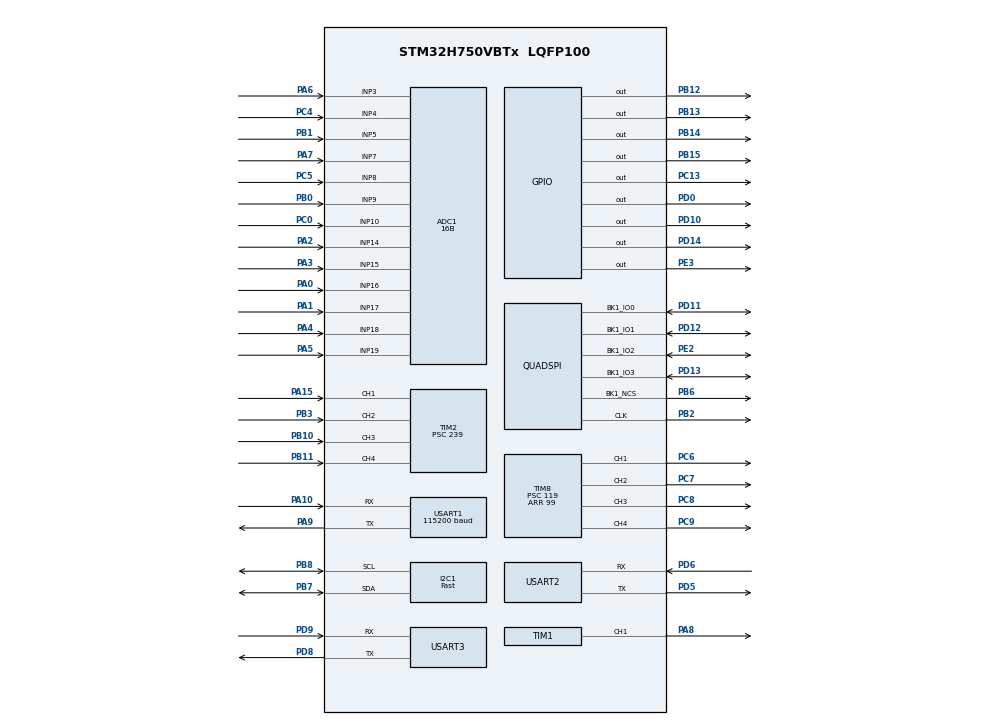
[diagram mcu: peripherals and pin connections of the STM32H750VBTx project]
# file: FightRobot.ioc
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ADC1.Channel-0\#ChannelRegularConversion=ADC_CHANNEL_3
ADC1.Channel-1\#ChannelRegularConversion=ADC_CHANNEL_4
ADC1.Channel-10\#ChannelRegularConversion=ADC_CHANNEL_17
ADC1.Channel-11\#ChannelRegularConversion=ADC_CHANNEL_18
ADC1.Channel-12\#ChannelRegularConversion=ADC_CHANNEL_19
ADC1.Channel-2\#ChannelRegularConversion=ADC_CHANNEL_5
ADC1.Channel-3\#ChannelRegularConversion=ADC_CHANNEL_7
ADC1.Channel-4\#ChannelRegularConversion=ADC_CHANNEL_8
ADC1.Channel-5\#ChannelRegularConversion=ADC_CHANNEL_9
ADC1.Channel-6\#ChannelRegularConversion=ADC_CHANNEL_10
ADC1.Channel-7\#ChannelRegularConversion=ADC_CHANNEL_14
ADC1.Channel-8\#ChannelRegularConversion=ADC_CHANNEL_15
ADC1.Channel-9\#ChannelRegularConversion=ADC_CHANNEL_16
ADC1.ClockPrescaler=ADC_CLOCK_ASYNC_DIV8
ADC1.ClockPrescalerADC3=ADC_CLOCK_ASYNC_DIV8
ADC1.ContinuousConvMode=ENABLE
ADC1.ConversionDataManagement=ADC_CONVERSIONDATA_DMA_CIRCULAR
ADC1.DiscontinuousConvMode=DISABLE
ADC1.EOCSelection=ADC_EOC_SEQ_CONV
ADC1.NbrOfConversion=13
ADC1.NbrOfConversionFlag=1
ADC1.OffsetNumber-0\#ChannelRegularConversion=ADC_OFFSET_NONE
ADC1.OffsetNumber-1\#ChannelRegularConversion=ADC_OFFSET_NONE
ADC1.OffsetNumber-10\#ChannelRegularConversion=ADC_OFFSET_NONE
ADC1.OffsetNumber-11\#ChannelRegularConversion=ADC_OFFSET_NONE
ADC1.OffsetNumber-12\#ChannelRegularConversion=ADC_OFFSET_NONE
ADC1.OffsetNumber-2\#ChannelRegularConversion=ADC_OFFSET_NONE
ADC1.OffsetNumber-3\#ChannelRegularConversion=ADC_OFFSET_NONE
ADC1.OffsetNumber-4\#ChannelRegularConversion=ADC_OFFSET_NONE
ADC1.OffsetNumber-5\#ChannelRegularConversion=ADC_OFFSET_NONE
ADC1.OffsetNumber-6\#ChannelRegularConversion=ADC_OFFSET_NONE
ADC1.OffsetNumber-7\#ChannelRegularConversion=ADC_OFFSET_NONE
ADC1.OffsetNumber-8\#ChannelRegularConversion=ADC_OFFSET_NONE
ADC1.OffsetNumber-9\#ChannelRegularConversion=ADC_OFFSET_NONE
ADC1.OffsetSignedSaturation-0\#ChannelRegularConversion=DISABLE
ADC1.OffsetSignedSaturation-1\#ChannelRegularConversion=DISABLE
ADC1.OffsetSignedSaturation-10\#ChannelRegularConversion=DISABLE
ADC1.OffsetSignedSaturation-11\#ChannelRegularConversion=DISABLE
ADC1.OffsetSignedSaturation-12\#ChannelRegularConversion=DISABLE
ADC1.OffsetSignedSaturation-2\#ChannelRegularConversion=DISABLE
ADC1.OffsetSignedSaturation-3\#ChannelRegularConversion=DISABLE
ADC1.OffsetSignedSaturation-4\#ChannelRegularConversion=DISABLE
ADC1.OffsetSignedSaturation-5\#ChannelRegularConversion=DISABLE
ADC1.OffsetSignedSaturation-6\#ChannelRegularConversion=DISABLE
ADC1.OffsetSignedSaturation-7\#ChannelRegularConversion=DISABLE
ADC1.OffsetSignedSaturation-8\#ChannelRegularConversion=DISABLE
ADC1.OffsetSignedSaturation-9\#ChannelRegularConversion=DISABLE
ADC1.Overrun=ADC_OVR_DATA_OVERWRITTEN
ADC1.OversamplingMode=ENABLE
ADC1.Rank-0\#ChannelRegularConversion=1
ADC1.Rank-1\#ChannelRegularConversion=2
ADC1.Rank-10\#ChannelRegularConversion=11
ADC1.Rank-11\#ChannelRegularConversion=12
ADC1.Rank-12\#ChannelRegularConversion=13
ADC1.Rank-2\#ChannelRegularConversion=3
ADC1.Rank-3\#ChannelRegularConversion=4
ADC1.Rank-4\#ChannelRegularConversion=5
ADC1.Rank-5\#ChannelRegularConversion=6
ADC1.Rank-6\#ChannelRegularConversion=7
ADC1.Rank-7\#ChannelRegularConversion=8
ADC1.Rank-8\#ChannelRegularConversion=9
ADC1.Rank-9\#ChannelRegularConversion=10
ADC1.Ratio=16
ADC1.Resolution=ADC_RESOLUTION_16B
ADC1.RightBitShift=ADC_RIGHTBITSHIFT_4
ADC1.SamplingTime-0\#ChannelRegularConversion=ADC_SAMPLETIME_64CYCLES_5
ADC1.SamplingTime-1\#ChannelRegularConversion=ADC_SAMPLETIME_64CYCLES_5
ADC1.SamplingTime-10\#ChannelRegularConversion=ADC_SAMPLETIME_64CYCLES_5
ADC1.SamplingTime-11\#ChannelRegularConversion=ADC_SAMPLETIME_64CYCLES_5
ADC1.SamplingTime-12\#ChannelRegularConversion=ADC_SAMPLETIME_64CYCLES_5
ADC1.SamplingTime-2\#ChannelRegularConversion=ADC_SAMPLETIME_64CYCLES_5
ADC1.SamplingTime-3\#ChannelRegularConversion=ADC_SAMPLETIME_64CYCLES_5
ADC1.SamplingTime-4\#ChannelRegularConversion=ADC_SAMPLETIME_64CYCLES_5
ADC1.SamplingTime-5\#ChannelRegularConversion=ADC_SAMPLETIME_64CYCLES_5
ADC1.SamplingTime-6\#ChannelRegularConversion=ADC_SAMPLETIME_64CYCLES_5
ADC1.SamplingTime-7\#ChannelRegularConversion=ADC_SAMPLETIME_64CYCLES_5
ADC1.SamplingTime-8\#ChannelRegularConversion=ADC_SAMPLETIME_64CYCLES_5
ADC1.SamplingTime-9\#ChannelRegularConversion=ADC_SAMPLETIME_64CYCLES_5
ADC1.master=1
CORTEX_M7.AccessPermission_Spec=MPU_REGION_FULL_ACCESS
CORTEX_M7.BaseAddress_Spec=0x24000000
CORTEX_M7.CPU_DCache=Enabled
CORTEX_M7.CPU_ICache=Enabled
CORTEX_M7.DisableExec_Spec=MPU_INSTRUCTION_ACCESS_ENABLE
CORTEX_M7.Enable-Cortex_Memory_Protection_Unit_Region15_Settings=__NULL
CORTEX_M7.Enable-Cortex_Memory_Protection_Unit_Region1_Settings=__NULL
CORTEX_M7.Enable-Cortex_Memory_Protection_Unit_Region2_Settings=__NULL
CORTEX_M7.IsShareable_Spec=MPU_ACCESS_NOT_SHAREABLE
CORTEX_M7.MPU_Control=MPU_HFNMI_PRIVDEF
CORTEX_M7.Size_Spec=MPU_REGION_SIZE_512KB
CORTEX_M7.SubRegionDisable_Spec=0x00
CORTEX_M7.TypeExtField_Spec=MPU_TEX_LEVEL1
CORTEX_M7.default_mode_Activation=1
Dma.ADC1.4.Direction=DMA_PERIPH_TO_MEMORY
Dma.ADC1.4.EventEnable=DISABLE
Dma.ADC1.4.FIFOMode=DMA_FIFOMODE_DISABLE
Dma.ADC1.4.Instance=DMA1_Stream0
Dma.ADC1.4.MemDataAlignment=DMA_MDATAALIGN_HALFWORD
Dma.ADC1.4.MemInc=DMA_MINC_ENABLE
Dma.ADC1.4.Mode=DMA_CIRCULAR
Dma.ADC1.4.PeriphDataAlignment=DMA_PDATAALIGN_HALFWORD
Dma.ADC1.4.PeriphInc=DMA_PINC_DISABLE
Dma.ADC1.4.Polarity=HAL_DMAMUX_REQ_GEN_RISING
Dma.ADC1.4.Priority=DMA_PRIORITY_LOW
Dma.ADC1.4.RequestNumber=1
Dma.ADC1.4.SignalID=NONE
Dma.ADC1.4.SyncEnable=DISABLE
Dma.ADC1.4.SyncPolarity=HAL_DMAMUX_SYNC_NO_EVENT
Dma.ADC1.4.SyncRequestNumber=1
Dma.ADC1.4.SyncSignalID=NONE
Dma.Request0=USART2_RX
Dma.Request1=USART2_TX
Dma.Request2=USART1_TX
Dma.Request3=USART1_RX
Dma.Request4=ADC1
Dma.Request5=USART3_RX
Dma.Request6=USART3_TX
Dma.USART1_RX.3.Direction=DMA_PERIPH_TO_MEMORY
Dma.USART1_RX.3.EventEnable=DISABLE
Dma.USART1_RX.3.FIFOMode=DMA_FIFOMODE_DISABLE
Dma.USART1_RX.3.Instance=DMA1_Stream6
Dma.USART1_RX.3.MemDataAlignment=DMA_MDATAALIGN_BYTE
Dma.USART1_RX.3.MemInc=DMA_MINC_ENABLE
Dma.USART1_RX.3.Mode=DMA_CIRCULAR
Dma.USART1_RX.3.PeriphDataAlignment=DMA_PDATAALIGN_BYTE
Dma.USART1_RX.3.PeriphInc=DMA_PINC_DISABLE
Dma.USART1_RX.3.Polarity=HAL_DMAMUX_REQ_GEN_RISING
Dma.USART1_RX.3.Priority=DMA_PRIORITY_HIGH
Dma.USART1_RX.3.RequestNumber=1
Dma.USART1_RX.3.SignalID=NONE
Dma.USART1_RX.3.SyncEnable=DISABLE
Dma.USART1_RX.3.SyncPolarity=HAL_DMAMUX_SYNC_NO_EVENT
Dma.USART1_RX.3.SyncRequestNumber=1
Dma.USART1_RX.3.SyncSignalID=NONE
Dma.USART1_TX.2.Direction=DMA_MEMORY_TO_PERIPH
Dma.USART1_TX.2.EventEnable=DISABLE
Dma.USART1_TX.2.FIFOMode=DMA_FIFOMODE_DISABLE
Dma.USART1_TX.2.Instance=DMA1_Stream5
Dma.USART1_TX.2.MemDataAlignment=DMA_MDATAALIGN_BYTE
Dma.USART1_TX.2.MemInc=DMA_MINC_ENABLE
Dma.USART1_TX.2.Mode=DMA_CIRCULAR
Dma.USART1_TX.2.PeriphDataAlignment=DMA_PDATAALIGN_BYTE
Dma.USART1_TX.2.PeriphInc=DMA_PINC_DISABLE
Dma.USART1_TX.2.Polarity=HAL_DMAMUX_REQ_GEN_RISING
Dma.USART1_TX.2.Priority=DMA_PRIORITY_HIGH
Dma.USART1_TX.2.RequestNumber=1
Dma.USART1_TX.2.SignalID=NONE
Dma.USART1_TX.2.SyncEnable=DISABLE
Dma.USART1_TX.2.SyncPolarity=HAL_DMAMUX_SYNC_NO_EVENT
Dma.USART1_TX.2.SyncRequestNumber=1
Dma.USART1_TX.2.SyncSignalID=NONE
Dma.USART2_RX.0.Direction=DMA_PERIPH_TO_MEMORY
Dma.USART2_RX.0.EventEnable=DISABLE
Dma.USART2_RX.0.FIFOMode=DMA_FIFOMODE_DISABLE
Dma.USART2_RX.0.Instance=DMA1_Stream1
Dma.USART2_RX.0.MemDataAlignment=DMA_MDATAALIGN_BYTE
Dma.USART2_RX.0.MemInc=DMA_MINC_ENABLE
Dma.USART2_RX.0.Mode=DMA_CIRCULAR
Dma.USART2_RX.0.PeriphDataAlignment=DMA_PDATAALIGN_BYTE
Dma.USART2_RX.0.PeriphInc=DMA_PINC_DISABLE
Dma.USART2_RX.0.Polarity=HAL_DMAMUX_REQ_GEN_RISING
Dma.USART2_RX.0.Priority=DMA_PRIORITY_HIGH
Dma.USART2_RX.0.RequestNumber=1
Dma.USART2_RX.0.SignalID=NONE
Dma.USART2_RX.0.SyncEnable=DISABLE
Dma.USART2_RX.0.SyncPolarity=HAL_DMAMUX_SYNC_NO_EVENT
Dma.USART2_RX.0.SyncRequestNumber=1
Dma.USART2_RX.0.SyncSignalID=NONE
Dma.USART2_TX.1.Direction=DMA_MEMORY_TO_PERIPH
Dma.USART2_TX.1.EventEnable=DISABLE
Dma.USART2_TX.1.FIFOMode=DMA_FIFOMODE_DISABLE
Dma.USART2_TX.1.Instance=DMA1_Stream2
Dma.USART2_TX.1.MemDataAlignment=DMA_MDATAALIGN_BYTE
Dma.USART2_TX.1.MemInc=DMA_MINC_ENABLE
Dma.USART2_TX.1.Mode=DMA_CIRCULAR
Dma.USART2_TX.1.PeriphDataAlignment=DMA_PDATAALIGN_BYTE
Dma.USART2_TX.1.PeriphInc=DMA_PINC_DISABLE
Dma.USART2_TX.1.Polarity=HAL_DMAMUX_REQ_GEN_RISING
Dma.USART2_TX.1.Priority=DMA_PRIORITY_HIGH
Dma.USART2_TX.1.RequestNumber=1
Dma.USART2_TX.1.SignalID=NONE
Dma.USART2_TX.1.SyncEnable=DISABLE
Dma.USART2_TX.1.SyncPolarity=HAL_DMAMUX_SYNC_NO_EVENT
Dma.USART2_TX.1.SyncRequestNumber=1
Dma.USART2_TX.1.SyncSignalID=NONE
Dma.USART3_RX.5.Direction=DMA_PERIPH_TO_MEMORY
Dma.USART3_RX.5.EventEnable=DISABLE
Dma.USART3_RX.5.FIFOMode=DMA_FIFOMODE_DISABLE
Dma.USART3_RX.5.Instance=DMA1_Stream3
Dma.USART3_RX.5.MemDataAlignment=DMA_MDATAALIGN_BYTE
Dma.USART3_RX.5.MemInc=DMA_MINC_ENABLE
Dma.USART3_RX.5.Mode=DMA_CIRCULAR
Dma.USART3_RX.5.PeriphDataAlignment=DMA_PDATAALIGN_BYTE
Dma.USART3_RX.5.PeriphInc=DMA_PINC_DISABLE
Dma.USART3_RX.5.Polarity=HAL_DMAMUX_REQ_GEN_RISING
Dma.USART3_RX.5.Priority=DMA_PRIORITY_HIGH
Dma.USART3_RX.5.RequestNumber=1
Dma.USART3_RX.5.SignalID=NONE
Dma.USART3_RX.5.SyncEnable=DISABLE
Dma.USART3_RX.5.SyncPolarity=HAL_DMAMUX_SYNC_NO_EVENT
Dma.USART3_RX.5.SyncRequestNumber=1
Dma.USART3_RX.5.SyncSignalID=NONE
Dma.USART3_TX.6.Direction=DMA_MEMORY_TO_PERIPH
Dma.USART3_TX.6.EventEnable=DISABLE
Dma.USART3_TX.6.FIFOMode=DMA_FIFOMODE_DISABLE
Dma.USART3_TX.6.Instance=DMA1_Stream4
Dma.USART3_TX.6.MemDataAlignment=DMA_MDATAALIGN_BYTE
Dma.USART3_TX.6.MemInc=DMA_MINC_ENABLE
Dma.USART3_TX.6.Mode=DMA_CIRCULAR
Dma.USART3_TX.6.PeriphDataAlignment=DMA_PDATAALIGN_BYTE
Dma.USART3_TX.6.PeriphInc=DMA_PINC_DISABLE
Dma.USART3_TX.6.Polarity=HAL_DMAMUX_REQ_GEN_RISING
Dma.USART3_TX.6.Priority=DMA_PRIORITY_HIGH
Dma.USART3_TX.6.RequestNumber=1
Dma.USART3_TX.6.SignalID=NONE
Dma.USART3_TX.6.SyncEnable=DISABLE
Dma.USART3_TX.6.SyncPolarity=HAL_DMAMUX_SYNC_NO_EVENT
Dma.USART3_TX.6.SyncRequestNumber=1
Dma.USART3_TX.6.SyncSignalID=NONE
FREERTOS.BinarySemaphores01=Sem_IR_1,Dynamic,NULL;Sem_IR_2,Dynamic,NULL;Sem_IR_3,Dynamic,NULL;Sem_IR_4,Dynamic,NULL
FREERTOS.Events01=IR_EventGroup,Dynamic,NULL
FREERTOS.Queues01=UART1_Rx_Queue,256,uint8_t,0,Dynamic,NULL,NULL;IMU_Rx_Queue,16,uint32_t,0,Dynamic,NULL,NULL;Vision_Rx_Queue,16,uint32_t,0,Dynamic,NULL,NULL
FREERTOS.Tasks01=defaultTask,24,256,StartDefaultTask,Default,NULL,Dynamic,NULL,NULL;Motor_Task,48,512,StartMotor_Task,Default,NULL,Dynamic,NULL,NULL;Comm_Task,40,512,StartComm_Task,Default,NULL,Dynamic,NULL,NULL;Sensor_Task,32,512,StartSensor_Task,Default,NULL,Dynamic,NULL,NULL;Vision_Task,32,256,StartVision_Task,Default,NULL,Dynamic,NULL,NULL;Motion_Task,24,256,StartMotion_Task,Default,NULL,Dynamic,NULL,NULL;Angle_Task,47,256,StartAngle_Task,Default,NULL,Dynamic,NULL,NULL
FREERTOS.configCHECK_FOR_STACK_OVERFLOW=2
FREERTOS.configENABLE_FPU=1
FREERTOS.configTOTAL_HEAP_SIZE=65536
FREERTOS.configUSE_MALLOC_FAILED_HOOK=1
I2C1.I2C_Speed_Mode=I2C_Fast
I2C1.Timing=0x00B03FDB
Mcu.Family=STM32H7
Mcu.Name=STM32H750VBTx
Mcu.Package=LQFP100
NVIC.DMA1_Stream0_IRQn=true\:5\:0\:false\:false\:true\:true\:false\:true\:true
NVIC.DMA1_Stream1_IRQn=true\:5\:0\:false\:false\:true\:true\:false\:true\:true
NVIC.DMA1_Stream2_IRQn=true\:5\:0\:false\:false\:true\:true\:false\:true\:true
NVIC.DMA1_Stream3_IRQn=true\:5\:0\:false\:false\:true\:true\:false\:true\:true
NVIC.DMA1_Stream4_IRQn=true\:5\:0\:false\:false\:true\:true\:false\:true\:true
NVIC.DMA1_Stream5_IRQn=true\:5\:0\:false\:false\:true\:true\:false\:true\:true
NVIC.DMA1_Stream6_IRQn=true\:5\:0\:false\:false\:true\:true\:false\:true\:true
NVIC.PriorityGroup=NVIC_PRIORITYGROUP_4
NVIC.TIM2_IRQn=true\:5\:0\:false\:false\:true\:true\:true\:true\:true
NVIC.TIM7_IRQn=true\:15\:0\:false\:false\:true\:false\:false\:true\:true
NVIC.TimeBase=TIM7_IRQn
NVIC.TimeBaseIP=TIM7
NVIC.USART1_IRQn=true\:5\:0\:true\:false\:true\:true\:true\:true\:true
NVIC.USART2_IRQn=true\:5\:0\:true\:false\:true\:true\:true\:true\:true
NVIC.USART3_IRQn=true\:5\:0\:true\:false\:true\:true\:true\:true\:true
PA0.Mode=IN16-Single-Ended
PA0.Signal=ADC1_INP16
PA1.Mode=IN17-Single-Ended
PA1.Signal=ADC1_INP17
PA10.GPIO_PuPd=GPIO_NOPULL
PA10.GPIO_Speed=GPIO_SPEED_FREQ_VERY_HIGH
PA10.Mode=Asynchronous
PA10.Signal=USART1_RX
PA13\ (JTMS/SWDIO).Mode=Serial_Wire
PA13\ (JTMS/SWDIO).Signal=DEBUG_JTMS-SWDIO
PA14\ (JTCK/SWCLK).Mode=Serial_Wire
PA14\ (JTCK/SWCLK).Signal=DEBUG_JTCK-SWCLK
PA15\ (JTDI).Signal=S_TIM2_CH1_ETR
PA2.Signal=ADCx_INP14
PA3.Signal=ADCx_INP15
PA4.Signal=ADCx_INP18
PA5.Signal=ADCx_INP19
PA6.Signal=ADCx_INP3
PA7.Signal=ADCx_INP7
PA8.Signal=S_TIM1_CH1
PA9.GPIO_PuPd=GPIO_NOPULL
PA9.GPIO_Speed=GPIO_SPEED_FREQ_VERY_HIGH
PA9.Mode=Asynchronous
PA9.Signal=USART1_TX
PB0.Signal=ADCx_INP9
PB1.Signal=ADCx_INP5
PB10.Signal=S_TIM2_CH3
PB11.Signal=S_TIM2_CH4
PB12.Signal=GPIO_Output
PB13.Signal=GPIO_Output
PB14.Signal=GPIO_Output
PB15.Signal=GPIO_Output
PB2.GPIO_Speed=GPIO_SPEED_FREQ_VERY_HIGH
PB2.Mode=Single Bank 1
PB2.Signal=QUADSPI_CLK
PB3\ (JTDO/TRACESWO).Signal=S_TIM2_CH2
PB6.GPIO_Speed=GPIO_SPEED_FREQ_VERY_HIGH
PB6.Mode=Single Bank 1
PB6.Signal=QUADSPI_BK1_NCS
PB7.Mode=I2C
PB7.Signal=I2C1_SDA
PB8.Mode=I2C
PB8.Signal=I2C1_SCL
PC0.Signal=ADCx_INP10
PC13.GPIO_PuPd=GPIO_NOPULL
PC13.Signal=GPIO_Output
PC14-OSC32_IN\ (OSC32_IN).Mode=LSE-External-Oscillator
PC14-OSC32_IN\ (OSC32_IN).Signal=RCC_OSC32_IN
PC15-OSC32_OUT\ (OSC32_OUT).Mode=LSE-External-Oscillator
PC15-OSC32_OUT\ (OSC32_OUT).Signal=RCC_OSC32_OUT
PC4.Signal=ADCx_INP4
PC5.Signal=ADCx_INP8
PC6.Signal=S_TIM8_CH1
PC7.Signal=S_TIM8_CH2
PC8.Signal=S_TIM8_CH3
PC9.Signal=S_TIM8_CH4
PD0.GPIO_ModeDefaultOutputPP=GPIO_MODE_OUTPUT_OD
PD0.GPIO_PuPd=GPIO_PULLUP
PD0.GPIO_Speed=GPIO_SPEED_FREQ_HIGH
PD0.PinState=GPIO_PIN_SET
PD0.Signal=GPIO_Output
PD10.GPIO_ModeDefaultOutputPP=GPIO_MODE_OUTPUT_OD
PD10.GPIO_PuPd=GPIO_PULLUP
PD10.GPIO_Speed=GPIO_SPEED_FREQ_HIGH
PD10.PinState=GPIO_PIN_SET
PD10.Signal=GPIO_Output
PD11.GPIO_Speed=GPIO_SPEED_FREQ_VERY_HIGH
PD11.Mode=Single Bank 1
PD11.Signal=QUADSPI_BK1_IO0
PD12.GPIO_Speed=GPIO_SPEED_FREQ_VERY_HIGH
PD12.Mode=Single Bank 1
PD12.Signal=QUADSPI_BK1_IO1
PD13.GPIO_Speed=GPIO_SPEED_FREQ_VERY_HIGH
PD13.Mode=Single Bank 1
PD13.Signal=QUADSPI_BK1_IO3
PD14.GPIO_ModeDefaultOutputPP=GPIO_MODE_OUTPUT_OD
PD14.GPIO_PuPd=GPIO_PULLUP
PD14.GPIO_Speed=GPIO_SPEED_FREQ_HIGH
PD14.PinState=GPIO_PIN_SET
PD14.Signal=GPIO_Output
PD5.Mode=Asynchronous
PD5.Signal=USART2_TX
PD6.Mode=Asynchronous
PD6.Signal=USART2_RX
PD8.Mode=Asynchronous
PD8.Signal=USART3_TX
PD9.Mode=Asynchronous
PD9.Signal=USART3_RX
PE2.GPIO_Speed=GPIO_SPEED_FREQ_VERY_HIGH
PE2.Mode=Single Bank 1
PE2.Signal=QUADSPI_BK1_IO2
PE3.GPIO_ModeDefaultOutputPP=GPIO_MODE_OUTPUT_OD
PE3.GPIO_PuPd=GPIO_PULLUP
PE3.GPIO_Speed=GPIO_SPEED_FREQ_HIGH
PE3.PinState=GPIO_PIN_SET
PE3.Signal=GPIO_Output
PH0-OSC_IN\ (PH0).Mode=HSE-External-Oscillator
PH0-OSC_IN\ (PH0).Signal=RCC_OSC_IN
PH1-OSC_OUT\ (PH1).Mode=HSE-External-Oscillator
PH1-OSC_OUT\ (PH1).Signal=RCC_OSC_OUT
ProjectManager.HeapSize=0x200
ProjectManager.StackSize=0x400
ProjectManager.TargetToolchain=MDK-ARM V5.32
QUADSPI.ClockMode=QSPI_CLOCK_MODE_3
QUADSPI.ClockPrescaler=2
QUADSPI.FifoThreshold=32
QUADSPI.FlashSize=22
QUADSPI.SampleShifting=QSPI_SAMPLE_SHIFTING_HALFCYCLE
RCC.ADCFreq_Value=72000000
RCC.APB1Freq_Value=120000000
RCC.APB2Freq_Value=120000000
RCC.APB3Freq_Value=120000000
RCC.APB4Freq_Value=120000000
RCC.CortexFreq_Value=480000000
RCC.D1PPRE=RCC_APB3_DIV2
RCC.D2PPRE1=RCC_APB1_DIV2
RCC.D2PPRE2=RCC_APB2_DIV2
RCC.D3PPRE=RCC_APB4_DIV2
RCC.DIVM1=5
RCC.DIVM2=25
RCC.DIVN1=192
RCC.DIVN2=504
RCC.DIVP2=7
RCC.DIVQ1=4
RCC.DIVQ2=7
RCC.DIVR2=7
RCC.HCLKFreq_Value=240000000
RCC.HPRE=RCC_HCLK_DIV2
RCC.PLL1_VCO_SEL-AdvancedSettings=RCC_PLL1VCOMEDIUM
RCC.PLL3_VCI_Range-AdvancedSettings=RCC_PLL3VCIRANGE_1
RCC.PLLSourceVirtual=RCC_PLLSOURCE_HSE
RCC.PWR_Regulator_Voltage_Scale=PWR_REGULATOR_VOLTAGE_SCALE0
RCC.ProductRev=revV
RCC.RTCClockSelection=RCC_RTCCLKSOURCE_LSE
RCC.SYSCLKFreq_VALUE=480000000
RCC.SYSCLKSource=RCC_SYSCLKSOURCE_PLLCLK
RCC.USBCLockSelection=RCC_USBCLKSOURCE_HSI48
RCC.USBFreq_Value=48000000
SH.ADCx_INP10.0=ADC1_INP10,IN10-Single-Ended
SH.ADCx_INP14.0=ADC1_INP14,IN14-Single-Ended
SH.ADCx_INP15.0=ADC1_INP15,IN15-Single-Ended
SH.ADCx_INP18.0=ADC1_INP18,IN18-Single-Ended
SH.ADCx_INP19.0=ADC1_INP19,IN19-Single-Ended
SH.ADCx_INP3.0=ADC1_INP3,IN3-Single-Ended
SH.ADCx_INP4.0=ADC1_INP4,IN4-Single-Ended
SH.ADCx_INP5.0=ADC1_INP5,IN5-Single-Ended
SH.ADCx_INP7.0=ADC1_INP7,IN7-Single-Ended
SH.ADCx_INP8.0=ADC1_INP8,IN8-Single-Ended
SH.ADCx_INP9.0=ADC1_INP9,IN9-Single-Ended
SH.S_TIM1_CH1.0=TIM1_CH1,PWM Generation1 CH1
SH.S_TIM2_CH1_ETR.0=TIM2_CH1,Input_Capture1_from_TI1
SH.S_TIM2_CH2.0=TIM2_CH2,Input_Capture2_from_TI2
SH.S_TIM2_CH3.0=TIM2_CH3,Input_Capture3_from_TI3
SH.S_TIM2_CH4.0=TIM2_CH4,Input_Capture4_from_TI4
SH.S_TIM8_CH1.0=TIM8_CH1,PWM Generation1 CH1
SH.S_TIM8_CH2.0=TIM8_CH2,PWM Generation2 CH2
SH.S_TIM8_CH3.0=TIM8_CH3,PWM Generation3 CH3
SH.S_TIM8_CH4.0=TIM8_CH4,PWM Generation4 CH4
TIM1.AutoReloadPreload=TIM_AUTORELOAD_PRELOAD_ENABLE
TIM1.Channel-PWM\ Generation1\ CH1=TIM_CHANNEL_1
TIM1.Period=1999
TIM1.Prescaler=2399
TIM2.Channel-Input_Capture1_from_TI1=TIM_CHANNEL_1
TIM2.Channel-Input_Capture2_from_TI2=TIM_CHANNEL_2
TIM2.Channel-Input_Capture3_from_TI3=TIM_CHANNEL_3
TIM2.Channel-Input_Capture4_from_TI4=TIM_CHANNEL_4
TIM2.Prescaler=239
TIM8.AutoReloadPreload=TIM_AUTORELOAD_PRELOAD_ENABLE
TIM8.Channel-PWM\ Generation1\ CH1=TIM_CHANNEL_1
TIM8.Channel-PWM\ Generation2\ CH2=TIM_CHANNEL_2
TIM8.Channel-PWM\ Generation3\ CH3=TIM_CHANNEL_3
TIM8.Channel-PWM\ Generation4\ CH4=TIM_CHANNEL_4
TIM8.Period=99
TIM8.Prescaler=119
USART1.BaudRate=115200
USART1.VirtualMode-Asynchronous=VM_ASYNC
USART2.VirtualMode-Asynchronous=VM_ASYNC
USART3.VirtualMode-Asynchronous=VM_ASYNC
VP_FREERTOS_VS_CMSIS_V2.Mode=CMSIS_V2
VP_RTC_VS_RTC_Activate.Mode=RTC_Enabled
VP_SYS_VS_tim7.Mode=TIM7
VP_TIM1_VS_ClockSourceINT.Mode=Internal
VP_TIM2_VS_ClockSourceINT.Mode=Internal
VP_TIM8_VS_ClockSourceINT.Mode=Internal
board=custom

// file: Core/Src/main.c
/* USER CODE BEGIN Header */
/**
  ******************************************************************************
  * @file           : main.c
  * @brief          : Main program body
  ******************************************************************************
  * @attention
  *
  * Copyright (c) 2026 STMicroelectronics.
  * All rights reserved.

  * This software is licensed under terms that can be found in the LICENSE file
  * in the root directory of this software component.
  * If no LICENSE file comes with this software, it is provided AS-IS.
  *
  ******************************************************************************
  */
/* USER CODE END Header */
#include "main.h"
#include "cmsis_os.h"
#include "adc.h"
#include "dma.h"
#include "i2c.h"
#include "quadspi.h"
#include "rtc.h"
#include "tim.h"
#include "usart.h"
#include "gpio.h"

/* USER CODE BEGIN Includes */

#include <stdio.h>
#include "IMU.h"
#include "control.h"
#include "Motor.h"
#include "IR_Sensor.h"
#include "Machine_Vision.h"

/* USER CODE END Includes */

/* USER CODE BEGIN PD */

#define IMU_RX_BUFFER_SIZE  64     // 长度足够容纳至少几帧数据 (1帧是11字节)

/* USER CODE END PD */

/* USER CODE BEGIN PV */
uint32_t motor_capture_val[4] = {0}; // 记录每个通道�??新的计数�??
uint32_t motor_pulse_diff[4] = {0};  // 两个上升沿之间的差�??
uint32_t motor_pulse_count[4] = {0}; // 累计脉冲�??

uint32_t imu_rx_byte_count = 0;
__attribute__((aligned(32))) uint8_t imu_rx_buffer[IMU_RX_BUFFER_SIZE];

uint16_t adc_raw_data[13];
float grey_value[4];
float ir_distance[9];

uint8_t sw1, sw2, sw3, sw4; // 4???????

uint16_t laser_dist_1 = 0; // 激光测距 1
uint16_t laser_dist_2 = 0; // 激光测距 2

extern float motor_target_speed[4];

/* USER CODE END PV */

void SystemClock_Config(void);
static void MPU_Config(void);
void MX_FREERTOS_Init(void);

/* USER CODE BEGIN 0 */
extern osMessageQueueId_t UART1_Rx_QueueHandle;
extern osMessageQueueId_t Vision_Rx_QueueHandle;
/* USER CODE END 0 */

int main(void)
{

  /* MPU Configuration--------------------------------------------------------*/
  MPU_Config();

  /* Enable I-Cache---------------------------------------------------------*/
  SCB_EnableICache();

  /* Enable D-Cache---------------------------------------------------------*/
  SCB_EnableDCache();

  /* MCU Configuration--------------------------------------------------------*/

  /* Reset of all peripherals, Initializes the Flash interface and the Systick. */
  HAL_Init();

  /* Configure the system clock */
  SystemClock_Config();

  /* Initialize all configured peripherals */
  MX_GPIO_Init();
  MX_DMA_Init();
  MX_TIM2_Init();
  MX_ADC1_Init();
  MX_USART2_UART_Init();
  MX_USART3_UART_Init();
  MX_USART1_UART_Init();
  MX_QUADSPI_Init();
  MX_RTC_Init();
  MX_TIM8_Init();
  MX_TIM1_Init();
  MX_I2C1_Init();
  /* USER CODE BEGIN 2 */

  HAL_ADC_Start_DMA(&hadc1, (uint32_t*)adc_raw_data, 13);
  HAL_UARTEx_ReceiveToIdle_DMA(&huart3, imu_rx_buffer, IMU_RX_BUFFER_SIZE);
  MachineVision_Init(&huart2);

  Control_Init();

  /* USER CODE END 2 */

  /* Init scheduler */
  osKernelInitialize();  /* Call init function for freertos objects (in freertos.c) */
  MX_FREERTOS_Init();

  /* Start scheduler */
  osKernelStart();
  /* We should never get here as control is now taken by the scheduler */
  /* Infinite loop */
  while (1)
  {

  }
}

void SystemClock_Config(void)
{
  RCC_OscInitTypeDef RCC_OscInitStruct = {0};
  RCC_ClkInitTypeDef RCC_ClkInitStruct = {0};

  /** Supply configuration update enable
  */
  HAL_PWREx_ConfigSupply(PWR_LDO_SUPPLY);

  /** Configure the main internal regulator output voltage
  */
  __HAL_PWR_VOLTAGESCALING_CONFIG(PWR_REGULATOR_VOLTAGE_SCALE1);

  while(!__HAL_PWR_GET_FLAG(PWR_FLAG_VOSRDY)) {}

  __HAL_RCC_SYSCFG_CLK_ENABLE();
  __HAL_PWR_VOLTAGESCALING_CONFIG(PWR_REGULATOR_VOLTAGE_SCALE0);

  while(!__HAL_PWR_GET_FLAG(PWR_FLAG_VOSRDY)) {}

  /** Configure LSE Drive Capability
  */
  HAL_PWR_EnableBkUpAccess();
  __HAL_RCC_LSEDRIVE_CONFIG(RCC_LSEDRIVE_LOW);

  /** Initializes the RCC Oscillators according to the specified parameters
  * in the RCC_OscInitTypeDef structure.
  */
  RCC_OscInitStruct.OscillatorType = RCC_OSCILLATORTYPE_HSE|RCC_OSCILLATORTYPE_LSE;
  RCC_OscInitStruct.HSEState = RCC_HSE_ON;
  RCC_OscInitStruct.LSEState = RCC_LSE_ON;
  RCC_OscInitStruct.PLL.PLLState = RCC_PLL_ON;
  RCC_OscInitStruct.PLL.PLLSource = RCC_PLLSOURCE_HSE;
  RCC_OscInitStruct.PLL.PLLM = 5;
  RCC_OscInitStruct.PLL.PLLN = 192;
  RCC_OscInitStruct.PLL.PLLP = 2;
  RCC_OscInitStruct.PLL.PLLQ = 4;
  RCC_OscInitStruct.PLL.PLLR = 2;
  RCC_OscInitStruct.PLL.PLLRGE = RCC_PLL1VCIRANGE_2;
  RCC_OscInitStruct.PLL.PLLVCOSEL = RCC_PLL1VCOWIDE;
  RCC_OscInitStruct.PLL.PLLFRACN = 0;
  if (HAL_RCC_OscConfig(&RCC_OscInitStruct) != HAL_OK)
  {
    Error_Handler();
  }

  /** Initializes the CPU, AHB and APB buses clocks
  */
  RCC_ClkInitStruct.ClockType = RCC_CLOCKTYPE_HCLK|RCC_CLOCKTYPE_SYSCLK
                              |RCC_CLOCKTYPE_PCLK1|RCC_CLOCKTYPE_PCLK2
                              |RCC_CLOCKTYPE_D3PCLK1|RCC_CLOCKTYPE_D1PCLK1;
  RCC_ClkInitStruct.SYSCLKSource = RCC_SYSCLKSOURCE_PLLCLK;
  RCC_ClkInitStruct.SYSCLKDivider = RCC_SYSCLK_DIV1;
  RCC_ClkInitStruct.AHBCLKDivider = RCC_HCLK_DIV2;
  RCC_ClkInitStruct.APB3CLKDivider = RCC_APB3_DIV2;
  RCC_ClkInitStruct.APB1CLKDivider = RCC_APB1_DIV2;
  RCC_ClkInitStruct.APB2CLKDivider = RCC_APB2_DIV2;
  RCC_ClkInitStruct.APB4CLKDivider = RCC_APB4_DIV2;

  if (HAL_RCC_ClockConfig(&RCC_ClkInitStruct, FLASH_LATENCY_4) != HAL_OK)
  {
    Error_Handler();
  }
}

/* USER CODE BEGIN 4 */
#if defined ( __CC_ARM ) || defined (__ARMCC_VERSION)
#pragma import(__use_no_semihosting)
struct __FILE {
    int handle;
};
FILE __stdout;
FILE __stdin;
FILE __stderr;
void _sys_exit(int x) {
    x = x;
}
void _ttywrch(int ch) {
}
#endif

int fputc(int ch, FILE *f)
{
    uint8_t temp = (uint8_t)ch;
    HAL_UART_Transmit(&huart1, &temp, 1, HAL_MAX_DELAY);
    return ch;
}

void HAL_UARTEx_RxEventCallback(UART_HandleTypeDef *huart, uint16_t Size)
{    // 调用遥控器解析�?�辑(USART1在里面会被识别处�??)
    Control_UART_RxCallback(huart, Size);
  MachineVision_RxEventCallback(huart, Size);

  if ((huart->Instance == USART2) && (Vision_Rx_QueueHandle != NULL))
  {
    uint32_t notify_msg = 1;
    (void)osMessageQueuePut(Vision_Rx_QueueHandle, &notify_msg, 0, 0);
  }

    static uint16_t old_pos = 0;
    if (huart->Instance == USART3)  // 匹配 IMU 的串�?????
    {
        /* Invalidate D-Cache to ensure CPU reads the latest data written by DMA */
        SCB_InvalidateDCache_by_Addr((uint32_t *)((uint32_t)imu_rx_buffer & ~0x1F), (IMU_RX_BUFFER_SIZE + 31) & ~0x1F);

        /* 遍历 DMA 刚刚搬运完的这批字节，挨个喂给状态机去解�????? */
        uint16_t new_pos = Size;
        /* Calculate how many bytes have been received since last callback */
        uint16_t length = (new_pos + IMU_RX_BUFFER_SIZE - old_pos) % IMU_RX_BUFFER_SIZE;
        /* If TC interrupt sets Size to IMU_RX_BUFFER_SIZE and old_pos is 0, length would be 0, so handle full buffer */
        if (length == 0 && new_pos != old_pos)
        {
            length = IMU_RX_BUFFER_SIZE;
        }

        for (uint16_t i = 0; i < length; i++)
        {
            IMU_ReceiveByte(imu_rx_buffer[old_pos]);
            old_pos++;
            if (old_pos >= IMU_RX_BUFFER_SIZE)
            {
                old_pos = 0;
            }
        }
    }
}

// 这个回调函数�??? HAL 库在 TIM2 捕获事件发生时调用，负责计算每个电机的脉冲差值和累计脉冲�???
void HAL_TIM_IC_CaptureCallback(TIM_HandleTypeDef *htim)
{
    if (htim->Instance == TIM2)
    {
        uint32_t current_val = 0;

        switch (htim->Channel)
        {
            case HAL_TIM_ACTIVE_CHANNEL_1: // 电机 4 (MOTOR_4) -> 数组索引 3
                current_val = HAL_TIM_ReadCapturedValue(htim, TIM_CHANNEL_1);
                motor_pulse_diff[3] = current_val - motor_capture_val[3];
                motor_capture_val[3] = current_val;
                motor_pulse_count[3]++; // 累计脉冲
                break;

            case HAL_TIM_ACTIVE_CHANNEL_2: // 电机 1 (MOTOR_1) -> 数组索引 0
                current_val = HAL_TIM_ReadCapturedValue(htim, TIM_CHANNEL_2);
                motor_pulse_diff[0] = current_val - motor_capture_val[0];
                motor_capture_val[0] = current_val;
                motor_pulse_count[0]++; // 累计脉冲
                break;

            case HAL_TIM_ACTIVE_CHANNEL_3: // 电机 2 (MOTOR_2) -> 数组索引 1
                current_val = HAL_TIM_ReadCapturedValue(htim, TIM_CHANNEL_3);
                motor_pulse_diff[1] = current_val - motor_capture_val[1];
                motor_capture_val[1] = current_val;
                motor_pulse_count[1]++; // 累计脉冲
                break;

            case HAL_TIM_ACTIVE_CHANNEL_4: // 电机 3 (MOTOR_3) -> 数组索引 2
                current_val = HAL_TIM_ReadCapturedValue(htim, TIM_CHANNEL_4);
                motor_pulse_diff[2] = current_val - motor_capture_val[2];
                motor_capture_val[2] = current_val;
                motor_pulse_count[2]++; // 累计脉冲
                break;

            default:
                break;
        }
    }
}

void IMU_HW_SerialSend(uint8_t *data, uint16_t len)
{
  HAL_UART_Transmit(&huart3, data, len, 100);
}

void HAL_UART_ErrorCallback(UART_HandleTypeDef *huart)
{
    if (huart->Instance == USART3)
    {
        __HAL_UART_CLEAR_FLAG(huart, UART_CLEAR_OREF | UART_CLEAR_NEF | UART_CLEAR_PEF | UART_CLEAR_FEF);
        HAL_UARTEx_ReceiveToIdle_DMA(huart, imu_rx_buffer, IMU_RX_BUFFER_SIZE);
    }
    else if (huart->Instance == USART1)
    {
        __HAL_UART_CLEAR_FLAG(huart, UART_CLEAR_OREF | UART_CLEAR_NEF | UART_CLEAR_PEF | UART_CLEAR_FEF);
        Control_Init();
    }
    else if (huart->Instance == USART2)
    {
        __HAL_UART_CLEAR_FLAG(huart, UART_CLEAR_OREF | UART_CLEAR_NEF | UART_CLEAR_PEF | UART_CLEAR_FEF);
        MachineVision_Init(huart);
    }
}

/* USER CODE END 4 */

/* MPU Configuration */

void MPU_Config(void)
{
  MPU_Region_InitTypeDef MPU_InitStruct = {0};

  /* Disables the MPU */
  HAL_MPU_Disable();

  /** Initializes and configures the Region and the memory to be protected
  */
  MPU_InitStruct.Enable = MPU_REGION_ENABLE;
  MPU_InitStruct.Number = MPU_REGION_NUMBER0;
  MPU_InitStruct.BaseAddress = 0x24000000;
  MPU_InitStruct.Size = MPU_REGION_SIZE_512KB;
  MPU_InitStruct.SubRegionDisable = 0x00;
  MPU_InitStruct.TypeExtField = MPU_TEX_LEVEL1;
  MPU_InitStruct.AccessPermission = MPU_REGION_FULL_ACCESS;
  MPU_InitStruct.DisableExec = MPU_INSTRUCTION_ACCESS_ENABLE;
  MPU_InitStruct.IsShareable = MPU_ACCESS_NOT_SHAREABLE;
  MPU_InitStruct.IsCacheable = MPU_ACCESS_NOT_CACHEABLE;
  MPU_InitStruct.IsBufferable = MPU_ACCESS_NOT_BUFFERABLE;

  HAL_MPU_ConfigRegion(&MPU_InitStruct);
  /* Enables the MPU */
  HAL_MPU_Enable(MPU_HFNMI_PRIVDEF);

}

void HAL_TIM_PeriodElapsedCallback(TIM_HandleTypeDef *htim)
{
  if (htim->Instance == TIM7) {
    HAL_IncTick();
  }
}

void Error_Handler(void)
{
  __disable_irq();
  while (1)
  {
  }
}

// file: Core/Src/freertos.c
/* USER CODE BEGIN Header */
/**
  ******************************************************************************
  * File Name          : freertos.c
  * Description        : Code for freertos applications
  ******************************************************************************
  * @attention
  *
  * Copyright (c) 2026 STMicroelectronics.
  * All rights reserved.
  *
  * This software is licensed under terms that can be found in the LICENSE file
  * in the root directory of this software component.
  * If no LICENSE file comes with this software, it is provided AS-IS.
  *
  ******************************************************************************
  */
/* USER CODE END Header */

#include "FreeRTOS.h"
#include "task.h"
#include "main.h"
#include "cmsis_os.h"

/* USER CODE BEGIN Includes */
#include "IMU.h"
#include <stdio.h>
#include "Motor.h"
#include "IR.h"
#include "Grey.h"
#include "tim.h"  // 包含定时器头文件
#include "PID.h"
#include "IR_Sensor.h"
#include "control.h"
#include "Servo.h"
#include "Motion.h"
#include "Machine_Vision.h"
#include "SoftI2C.h"
#include "TOF050C.h"
/* USER CODE END Includes */

/* USER CODE BEGIN PTD */

#include "config.h"
/* USER CODE END PTD */

/* USER CODE BEGIN Variables */
extern uint32_t imu_rx_byte_count;

volatile uint8_t global_vision_target = 0;   // 视觉传来的实时目标 tag_type
volatile float global_vision_yaw = 0.0f;     // 视觉传来的实时偏航角 yaw
volatile uint8_t is_vision_debug_mode = 0;    // 0=关, 1=安全只读模式, 2=动力调试模式
volatile uint32_t last_vision_tick   = 0;    // 记录上一帧视觉数据的时间戳 (ms)

extern uint16_t adc_raw_data[13];
extern float grey_value[4];
extern float ir_distance[9];

extern uint32_t motor_pulse_diff[4];
extern uint32_t motor_pulse_count[4];

extern uint8_t sw1, sw2, sw3, sw4; // 4路光电开关状态

float motor_rpm[4] = {0.0f};       // 保存4个电机的实时转速 (RPM)
float motor_rpm_norm[4] = {0.0f};  // 归一化后的转速 (-100 ~ 100)
PID_t motor_pid[4];                // 4个电机的PID控制结构体
float motor_target_speed[4] = {0.0f, 0.0f,0.0f, 0.0f}; // 目标转速
//一号轮右前轮，二号轮左前轮，三号轮右后轮，四号轮左后轮

PID_t Angle_pid[1];                   // 姿�?�控制PID结构体（单�?�道，控制机器人绕垂直轴的旋转）
float target_angle = 0.0f;            // 姿�?�控制的目标角度（单位：度，范围 -180 ~ 180）
float current_angle = 0.0f;           // 姿�?�控制的当前角度（单位：度，范围 -180 ~ 180）

/* 运动模式控制 */
uint8_t control_mode = 0;             // 0=遥控模式, 1=自动控制模式
uint8_t angle_control_enabled = 0;    // 0=禁用角度环, 1=启用角度环
uint8_t angle_control_prev = 0;       // 上一个周期的角度环启用状态，用于检测状态变化
uint32_t last_buttons = 0;            // 记录上一次的 button 值，用于检测按钮状态变化
/* 摇杆和角度环的分离控制 */
float motor_rc_speed[4] = {0.0f};     // 摇杆基础速度指令 (前后/左右)
float motor_angle_speed[4] = {0.0f};  // 角度环转向修正指令

/* ===== 自主登台与软启动参数配置（可根据实测微调） ===== */
#define SOFT_START_CONFIRM_CNT     5       /* 连续确认次数(防抖)，5次 x 20ms = 100ms */
#define CLIMB_SPEED                (-100)  /* 后退冲台的速度(-100为全速) */
#define CLIMB_LEFT_SPEED_LIMIT     (-100)  /* 左侧轮组(1,3)冲台速度 (-100为满速，可微调以纠正物理不对称导致的歪斜) */
#define CLIMB_RIGHT_SPEED_LIMIT    (-85)  /* 右侧轮组(2,4)冲台速度 (-100为满速，可微调以纠正物理不对称导致的歪斜) */
#define GREY_GRADUAL_FILTER_CNT    6       /* 连续采样次数，6 x 20ms = 120ms */

#define ONSTAGE_GREY_SUCCESS_THRESHOLD 140.0f /* 台上灰度成功阈值，小于此值代表已成功上台 */
#define DIST_CLOSE_THRESHOLD       30.0f   /* 判定靠墙/边缘距离(cm) */
#define DIST_OPEN_THRESHOLD        100.0f  /* 判定开阔距离(cm) */
#define CORNER_OPEN_THRESHOLD      80.0f   /* 角落检测的开阔判定距离(cm) */
#define TOP_IR_THRESHOLD           60.0f   /* 顶部红外发射检测擂台台面开阔的距离(cm) */

#define SCAN_ROTATE_SPEED          15      /* 台下原地缓慢自转扫描的速度 */
#define SQUARING_SPEED             45      /* 向前顶墙对齐的速度 */
#define SQUARING_DURATION_MS       1200    /* 前进顶墙时间为固定的1.2秒(1200ms) */
#define CORNER_MOVE_MS             600     /* 角落避障开环移动时间(ms) */
#define HEADING_KP                 1.5f    /* 锁角倒退的闭环比例纠偏系数 */
#define HEADING_KD                 0.05f   /* 锁角倒退的闭环微分纠偏系数 */

#define CLIMB_ONSTAGE_DURATION_MS  2000    /* 台上冲坡持续时间(2秒) */
#define CLIMB_BLIND_DURATION_MS    1000    /* 登台盲冲刺阶段时间为1.0秒(1000ms)，期间忽略灰度传感器 */
#define CLIMB_OFFSTAGE_TIMEOUT_MS  1000    /* 登台后退时间为 1 秒 (1000ms)，到时立即刹车 */

/* 自主登台与软启动状态枚举 */
typedef enum {
    ROBOT_WAITING           = 0,   /* 等待中：等待用户用手遮挡左右红外 */
    ROBOT_ARMED             = 1,   /* 已就绪：等待用户松开双手 */
    ROBOT_LAUNCH_DECIDE     = 2,   /* 启动决策：自动读取底盘判定台上/台下 */
    ROBOT_CLIMBING_ONSTAGE  = 3,   /* 台上启动：直接静止不动 */
    ROBOT_SCANNING          = 4,   /* 台下扫描：无论如何先自转扫掠 */
    ROBOT_CORNER_ESCAPE     = 5,   /* 角落脱困：自转中发现角落后避障 + 90°对齐 */
    ROBOT_SQUARING          = 6,   /* 物理顶墙：向前以 SQUARING_SPEED 顶墙，并重置IMU Yaw轴 */
    ROBOT_CLIMBING_OFFSTAGE = 7,   /* 闭环冲台：向后倒车 + PD纠偏直走登台 */
    ROBOT_FINISHED          = 8,   /* 登台/测试完成：保持绝对静止 */
    ROBOT_RUNNING           = 9,   /* 运行状态：常规模式 */
    ROBOT_TEST_ROTATE_90    = 10,  /* 测试状态：输入Y后，小车逆时针连续转动90° */
    ROBOT_TEST_ROTATE_PREPARE = 11, /* 准备状态：输入Y后，在任务中安全重置偏航角并等待 */
    ROBOT_CLIMB_ROTATE_TO_DIR = 12, /* 登台状态：转动到指定方向 */
    ROBOT_CLIMB_FORWARD_UNTIL_UP_IR = 13, /* 登台状态：向前直走直到上方红外大于110 */
    ROBOT_CLIMB_FORWARD_UNTIL_WALL = 14,  /* 登台状态：向前直走直到满足红外壁障条件 */
    ROBOT_CLIMB_FORWARD_DELAY = 15,       /* 登台状态：前行延时1秒 */
    ROBOT_CLIMB_BACKWARD_FAST = 16,       /* 登台状态：全速向后冲台1秒 */
    ROBOT_TEST_ATTACK_PREPARE = 17,       /* 测试状态：自主识别并进攻准备 */
    ROBOT_TEST_ATTACK_RUNNING = 18,       /* 测试状态：自主识别并进攻识别中心 */
    ROBOT_TEST_ATTACK_MOVE    = 19,       /* 测试状态：自主识别并进攻后冲刺0.5S */
    ROBOT_FIGHT_ATTACK_MOVE   = 20,       /* 实战状态：追踪敌人直到撞边缘 */
    ROBOT_INIT_CLIMB          = 21,       /* 初始启动直冲登台阶段 */
    ROBOT_ALIGN_ORTHO         = 22        /* 掉台就近90度倍数方向对齐 */
} RobotState_e;

volatile RobotState_e robot_state = ROBOT_WAITING;  /* 状态机当前状态 */
static uint8_t  soft_start_confirm   = 0;  /* 遮挡确认防抖计数器 */
static uint8_t  soft_release_confirm = 0;  /* 松开确认防抖计数器 */
static uint32_t climb_start_tick     = 0;  /* 记录冲台开始的时间 */

/* 脱困/顶墙过程辅助变量 */
static uint8_t  corner_type          = 0;  /* 1:后左(B+L), 2:后右(B+R) */
static uint8_t  corner_phase         = 0;  /* 脱困阶段：0:移动阶段, 1:转向90°阶段 */
static uint32_t corner_start_tick    = 0;  /* 脱困段计时 */
static float    target_angle_lock    = 0.0f; /* 自主控制锁定航向角 */
static uint8_t  climb_pd_init        = 0;  /* 登台 PD 控制器初始化标志 */
static uint32_t squaring_start_tick  = 0;  /* 顶墙开始时间 */
static uint8_t  is_test_mode         = 0;  /* 是否为串口 'Y' 触发的 270° 测试模式 */

/* 软启动与掉台后登台状态监控变量 */
static uint8_t  onstage_confirmed     = 0;  /* 台上确认状态：0:未确认, 1:已确认 */
static uint32_t verification_start_tick = 0; /* 台上验证延时计时器 */

/* USER CODE END Variables */
/* Definitions for defaultTask */
osThreadId_t defaultTaskHandle;
const osThreadAttr_t defaultTask_attributes = {
  .name = "defaultTask",
  .stack_size = 256 * 4,
  .priority = (osPriority_t) osPriorityNormal,
};
/* Definitions for Motor_Task */
osThreadId_t Motor_TaskHandle;
const osThreadAttr_t Motor_Task_attributes = {
  .name = "Motor_Task",
  .stack_size = 512 * 4,
  .priority = (osPriority_t) osPriorityRealtime,
};
/* Definitions for Comm_Task */
osThreadId_t Comm_TaskHandle;
const osThreadAttr_t Comm_Task_attributes = {
  .name = "Comm_Task",
  .stack_size = 512 * 4,
  .priority = (osPriority_t) osPriorityHigh,
};
/* Definitions for Sensor_Task */
osThreadId_t Sensor_TaskHandle;
const osThreadAttr_t Sensor_Task_attributes = {
  .name = "Sensor_Task",
  .stack_size = 512 * 4,
  .priority = (osPriority_t) osPriorityAboveNormal,
};
/* Definitions for Vision_Task */
osThreadId_t Vision_TaskHandle;
const osThreadAttr_t Vision_Task_attributes = {
  .name = "Vision_Task",
  .stack_size = 256 * 4,
  .priority = (osPriority_t) osPriorityAboveNormal,
};
/* Definitions for Motion_Task */
osThreadId_t Motion_TaskHandle;
const osThreadAttr_t Motion_Task_attributes = {
  .name = "Motion_Task",
  .stack_size = 256 * 4,
  .priority = (osPriority_t) osPriorityNormal,
};
/* Definitions for Angle_Task */
osThreadId_t Angle_TaskHandle;
const osThreadAttr_t Angle_Task_attributes = {
  .name = "Angle_Task",
  .stack_size = 256 * 4,
  .priority = (osPriority_t) osPriorityHigh7,
};
/* Definitions for UART1_Rx_Queue */
osMessageQueueId_t UART1_Rx_QueueHandle;
const osMessageQueueAttr_t UART1_Rx_Queue_attributes = {
  .name = "UART1_Rx_Queue"
};
/* Definitions for IMU_Rx_Queue */
osMessageQueueId_t IMU_Rx_QueueHandle;
const osMessageQueueAttr_t IMU_Rx_Queue_attributes = {
  .name = "IMU_Rx_Queue"
};
/* Definitions for Vision_Rx_Queue */
osMessageQueueId_t Vision_Rx_QueueHandle;
const osMessageQueueAttr_t Vision_Rx_Queue_attributes = {
  .name = "Vision_Rx_Queue"
};
/* Definitions for Sem_IR_1 */
osSemaphoreId_t Sem_IR_1Handle;
const osSemaphoreAttr_t Sem_IR_1_attributes = {
  .name = "Sem_IR_1"
};
/* Definitions for Sem_IR_2 */
osSemaphoreId_t Sem_IR_2Handle;
const osSemaphoreAttr_t Sem_IR_2_attributes = {
  .name = "Sem_IR_2"
};
/* Definitions for Sem_IR_3 */
osSemaphoreId_t Sem_IR_3Handle;
const osSemaphoreAttr_t Sem_IR_3_attributes = {
  .name = "Sem_IR_3"
};
/* Definitions for Sem_IR_4 */
osSemaphoreId_t Sem_IR_4Handle;
const osSemaphoreAttr_t Sem_IR_4_attributes = {
  .name = "Sem_IR_4"
};
/* Definitions for IR_EventGroup */
osEventFlagsId_t IR_EventGroupHandle;
const osEventFlagsAttr_t IR_EventGroup_attributes = {
  .name = "IR_EventGroup"
};

void StartDefaultTask(void *argument);
void StartMotor_Task(void *argument);
void StartComm_Task(void *argument);
void StartSensor_Task(void *argument);
void StartVision_Task(void *argument);
void StartMotion_Task(void *argument);
void StartAngle_Task(void *argument);

void MX_FREERTOS_Init(void); /* (MISRA C 2004 rule 8.1) */

/* Hook prototypes */
void vApplicationStackOverflowHook(xTaskHandle xTask, signed char *pcTaskName);
void vApplicationMallocFailedHook(void);

/* USER CODE BEGIN 4 */
void vApplicationStackOverflowHook(xTaskHandle xTask, signed char *pcTaskName)
{
   /* Run time stack overflow checking is performed if
   configCHECK_FOR_STACK_OVERFLOW is defined to 1 or 2. This hook function is
   called if a stack overflow is detected. */
}
/* USER CODE END 4 */

/* USER CODE BEGIN 5 */
void vApplicationMallocFailedHook(void)
{
   /* vApplicationMallocFailedHook() will only be called if
   configUSE_MALLOC_FAILED_HOOK is set to 1 in FreeRTOSConfig.h. It is a hook
   function that will get called if a call to pvPortMalloc() fails.
   pvPortMalloc() is called internally by the kernel whenever a task, queue,
   timer or semaphore is created. It is also called by various parts of the
   demo application. If heap_1.c or heap_2.c are used, then the size of the
   heap available to pvPortMalloc() is defined by configTOTAL_HEAP_SIZE in
   FreeRTOSConfig.h, and the xPortGetFreeHeapSize() API function can be used
   to query the size of free heap space that remains (although it does not
   provide information on how the remaining heap might be fragmented). */
}
/* USER CODE END 5 */

void MX_FREERTOS_Init(void) {

  /* Create the semaphores(s) */
  /* creation of Sem_IR_1 */
  Sem_IR_1Handle = osSemaphoreNew(1, 1, &Sem_IR_1_attributes);

  /* creation of Sem_IR_2 */
  Sem_IR_2Handle = osSemaphoreNew(1, 1, &Sem_IR_2_attributes);

  /* creation of Sem_IR_3 */
  Sem_IR_3Handle = osSemaphoreNew(1, 1, &Sem_IR_3_attributes);

  /* creation of Sem_IR_4 */
  Sem_IR_4Handle = osSemaphoreNew(1, 1, &Sem_IR_4_attributes);

  /* Create the queue(s) */
  /* creation of UART1_Rx_Queue */
  UART1_Rx_QueueHandle = osMessageQueueNew (256, sizeof(uint8_t), &UART1_Rx_Queue_attributes);

  /* creation of IMU_Rx_Queue */
  IMU_Rx_QueueHandle = osMessageQueueNew (16, sizeof(uint32_t), &IMU_Rx_Queue_attributes);

  /* creation of Vision_Rx_Queue */
  Vision_Rx_QueueHandle = osMessageQueueNew (16, sizeof(uint32_t), &Vision_Rx_Queue_attributes);

  /* Create the thread(s) */
  /* creation of defaultTask */
  defaultTaskHandle = osThreadNew(StartDefaultTask, NULL, &defaultTask_attributes);

  /* creation of Motor_Task */
  Motor_TaskHandle = osThreadNew(StartMotor_Task, NULL, &Motor_Task_attributes);

  /* creation of Comm_Task */
  Comm_TaskHandle = osThreadNew(StartComm_Task, NULL, &Comm_Task_attributes);

  /* creation of Sensor_Task */
  Sensor_TaskHandle = osThreadNew(StartSensor_Task, NULL, &Sensor_Task_attributes);

  /* creation of Vision_Task */
  Vision_TaskHandle = osThreadNew(StartVision_Task, NULL, &Vision_Task_attributes);

  /* creation of Motion_Task */
  Motion_TaskHandle = osThreadNew(StartMotion_Task, NULL, &Motion_Task_attributes);

  /* creation of Angle_Task */
  Angle_TaskHandle = osThreadNew(StartAngle_Task, NULL, &Angle_Task_attributes);

  /* Create the event(s) */
  /* creation of IR_EventGroup */
  IR_EventGroupHandle = osEventFlagsNew(&IR_EventGroup_attributes);

}

void StartDefaultTask(void *argument)
{
  /* USER CODE BEGIN StartDefaultTask */
  /* Infinite loop */
  for(;;)
  {

    osDelay(1000);
  }
  /* USER CODE END StartDefaultTask */
}

void StartMotor_Task(void *argument)
{
  /* USER CODE BEGIN StartMotor_Task */

  /* 启动定时器PWM输出(依据Motor.c映射TIM8的1,2,3,4通道) */
  extern TIM_HandleTypeDef htim8;
  HAL_TIM_PWM_Start(&htim8, TIM_CHANNEL_1);
  HAL_TIM_PWM_Start(&htim8, TIM_CHANNEL_2);
  HAL_TIM_PWM_Start(&htim8, TIM_CHANNEL_3);
  HAL_TIM_PWM_Start(&htim8, TIM_CHANNEL_4);

  /* 在任务初始化中开启TIM2?????4个?道捕获中断 */
HAL_TIM_IC_Start_IT(&htim2, TIM_CHANNEL_1);
HAL_TIM_IC_Start_IT(&htim2, TIM_CHANNEL_2);
HAL_TIM_IC_Start_IT(&htim2, TIM_CHANNEL_3);
HAL_TIM_IC_Start_IT(&htim2, TIM_CHANNEL_4);

  /* PID 初始化 (电机速度控制)
     增加: 误差绝对值死区阈值(如 2.0f)，积分分离阈值(如 30.0f)
     当绝对?度离目标超过 30 时切断积分防超调；相差 2 以内视为到达目标平息抖动 */
  for(int i = 0; i < 4; i++) {
      // (pid, Kp, Ki, Kd, MaxOut, MaxIOut, DeadBand, I_Separation)
      // 积分分离阈值 500.0f：防止启动时积分饱和；误差 < 500 时 P 项可能不足，积分逐步参与
      // 纯 P 控制(Kp=0.65)可能难以达到目标，积分项帮助消除稳?误???
      PID_Init(&motor_pid[i], 0.65f, 0.20f, 0.02f, 100.0f, 100.0f, 1.0f, 500.0f);
  }

  uint32_t last_pulse_count[4] = {0};
  float filtered_speed[4] = {0.0f}; // 新增：用于平滑测速跳动的低?滤波数???
  uint32_t motor_print_tick = 0;

  /* Infinite loop */
  for(;;)
  {    /* 融合摇杆速度和角度环转向修正 */
    for (int i = 0; i < 4; i++) {
      motor_target_speed[i] = motor_rc_speed[i] + motor_angle_speed[i];
      /* 限制在 -100 ~ 100 范围内 */
      if (motor_target_speed[i] > 100.0f) motor_target_speed[i] = 100.0f;
      if (motor_target_speed[i] < -100.0f) motor_target_speed[i] = -100.0f;
    }
        /* 计算并更新转速（50ms周期） */
    for (int i = 0; i < 4; i++)
    {
      uint32_t current_count = motor_pulse_count[i];
      uint32_t delta = current_count - last_pulse_count[i];
      last_pulse_count[i] = current_count;

      /* 1. 计算原始 RPM (仅为当前周期捕获的脚冲数产生的转速) */
      motor_rpm[i] = (float)delta * 133.333333f;

      /* 2. 归一化到绝对速度的模 0 ~ 100 */
      float current_abs_speed = (motor_rpm[i] / 6400.0f) * 100.0f;
      if (current_abs_speed > 100.0f) current_abs_speed = 100.0f;

      /* 引入一阶低通滤波 (Exponential Moving Average Filter)*/

      filtered_speed[i] = 0.6f * filtered_speed[i] + 0.4f * current_abs_speed;

      float output = 0.0f;

      /* 当目标转速为0时，直接输出0，并清空PID，防止编码器无方向时死区闭环发散 */
      if (motor_target_speed[i] == 0.0f) {
          motor_rpm_norm[i] = 0.0f;
          filtered_speed[i] = 0.0f; // 滤波清零，防止再度起步时毛刺
          PID_Clear(&motor_pid[i]); // 清除PID积分状态
          output = 0.0f;
      } else {
          /* 我们依据目标速度的方向(正反)，为滤后的绝对转速加上符号 */
          if (motor_target_speed[i] < 0.0f) {
               motor_rpm_norm[i] = -filtered_speed[i];
          } else {
               motor_rpm_norm[i] = filtered_speed[i];
          }

          /* 3. PID 计算得出控制输出 [-100, 100] */
          if (is_vision_debug_mode == 1) {
              output = 0.0f;
              PID_Clear(&motor_pid[i]);
          } else if (robot_state == ROBOT_INIT_CLIMB) {
              if (i == 0 || i == 2) {
                  output = CLIMB_LEFT_SPEED_LIMIT;
              } else {
                  output = CLIMB_RIGHT_SPEED_LIMIT;
              }
              PID_Clear(&motor_pid[i]);
          } else if (robot_state == ROBOT_CLIMBING_OFFSTAGE) {
              /* 台下闭环登台阶段：旁路电机速度 PID，输出直接等于带角度纠偏的目标速度以保证最大出力 */
              output = motor_target_speed[i];
              PID_Clear(&motor_pid[i]);
          } else {
              output = PID_Calc(&motor_pid[i], motor_target_speed[i], motor_rpm_norm[i]);
          }
      }

      Motor_SetSpeed(MOTOR_1 + i, output);
    }

    /* 视觉调试模式下的数据打印 (频率为 5Hz, 即每 200ms) */
    if (is_vision_debug_mode > 0)
    {
      static uint32_t last_vision_debug_print = 0;
      if (HAL_GetTick() - last_vision_debug_print >= 200U)
      {
        last_vision_debug_print = HAL_GetTick();
        printf("[VisionDebug] Mode: %s | Target: %u | Yaw: %.1f | Expected Speeds: L=%.1f, R=%.1f\r\n",
               (is_vision_debug_mode == 1) ? "SAFE" : "ACTIVE",
               global_vision_target,
               global_vision_yaw,
               motor_target_speed[1],  // 左轮预期速度 (Index 1)
               motor_target_speed[0]   // 右轮预期速度 (Index 0)
        );
      }
    }

        /* 降低打印频率至 1Hz，使串口更清爽 */
        if (HAL_GetTick() - motor_print_tick >= 1000U) {
          motor_print_tick = HAL_GetTick();
          printf("RPM: %.1f, %.1f, %.1f, %.1f\r\n",
            motor_rpm_norm[0], motor_rpm_norm[1], motor_rpm_norm[2], motor_rpm_norm[3]);
        }

    osDelay(50);
  }
  /* USER CODE END StartMotor_Task */
}

void StartComm_Task(void *argument)
{
  /* USER CODE BEGIN StartComm_Task */
  uint32_t msg;
  uint32_t comm_print_tick = 0;
  /* Infinite loop */
  for(;;)
  {
    /* 等待 Sensor_Task 每 100ms 发来的触发信号 */
    if (osMessageQueueGet(IMU_Rx_QueueHandle, &msg, NULL, osWaitForever) == osOK)
    {
      /* 将多行传感器输出降频至 1Hz，加快上位机显示，使串口更清爽 */
      if (HAL_GetTick() - comm_print_tick >= 1000U) {
        comm_print_tick = HAL_GetTick();
        printf("Roll: %.2f, Pitch: %.2f, Yaw: %.2f, Temp: %.2f\r\n", IMU_Data.Roll, IMU_Data.Pitch, IMU_Data.Yaw, IMU_Data.Temp);
        printf("IR Dist: %.1f, %.1f, %.1f, %.1f, %.1f, %.1f, %.1f, %.1f, %.1f\r\n",
               ir_distance[0], ir_distance[1], ir_distance[2],
               ir_distance[3], ir_distance[4], ir_distance[5],
               ir_distance[6], ir_distance[7], ir_distance[8]);
        printf("Grey(F,B,L,R): %.1f, %.1f, %.1f, %.1f\r\n",grey_value[0], grey_value[1], grey_value[2], grey_value[3]);

        printf("Photoelectric(SW1~SW4): %d, %d, %d, %d\r\n", sw1, sw2, sw3, sw4);
        printf("Laser(1,2): %d, %d mm\r\n", laser_dist_1, laser_dist_2);
      }

      //printf("Motor Pulses: %lu, %lu, %lu, %lu\r\n",
      //        motor_pulse_count[0], motor_pulse_count[1], motor_pulse_count[2], motor_pulse_count[3]);
    }
  }
  /* USER CODE END StartComm_Task */
}

void StartSensor_Task(void *argument)
{
  /* USER CODE BEGIN StartSensor_Task */
  uint32_t trigger_msg = 1;
  Grey_Init();
  IR_Init();

  // 初始化两路 TOF200C 激光测距传感器 (软件 I2C 总线)
  TOF050C_Init(SOFT_I2C_BUS_1);
  TOF050C_Init(SOFT_I2C_BUS_2);

  /* Infinite loop */
  for(;;)
  {
    /* 先计算前4路灰度值 */
    Grey_CalculateValues(&adc_raw_data[0], grey_value);

    /* 计算红外测距 */
    IR_CalculateDistances(&adc_raw_data[4], ir_distance);

    /* 读取两路激光测距 */
    laser_dist_1 = TOF050C_ReadDistance(SOFT_I2C_BUS_1);
    laser_dist_2 = TOF050C_ReadDistance(SOFT_I2C_BUS_2);

    /*
     * 原红外光电引脚已被复用为激光软件 I2C 通信引脚。
     * 为避免 I2C 数据通信时的电平变化被误判为光电开关触发，
     * 禁用原物理引脚读取逻辑，将原光电状态变量恒设为 0。
     */
    sw1 = 0;
    sw2 = 0;
    sw3 = 0;
    sw4 = 0;

    /* 向队列发送触发标志给 Comm_Task */
    osMessageQueuePut(IMU_Rx_QueueHandle, &trigger_msg, 0, 0);

    /* 延迟10ms */
    osDelay(10);
  }
  /* USER CODE END StartSensor_Task */
}

void StartVision_Task(void *argument)
{
  /* USER CODE BEGIN StartVision_Task */
  uint32_t msg;
  MV_ParsedFrame_t frame;
  MV_Stats_t stats;
  uint32_t vision_print_tick = 0;

  /* Infinite loop */
  for(;;)
  {
    (void)osMessageQueueGet(Vision_Rx_QueueHandle, &msg, NULL, 100);

    while (MachineVision_GetFrame(&frame) != 0U)
    {
      if (frame.type == MV_FRAME_VISION)
      {
        global_vision_target = frame.data.vision.tag_type;
        global_vision_yaw = frame.data.vision.yaw_cdeg / 100.0f;
        last_vision_tick = HAL_GetTick();

        printf("VISION seq=%u tag_id=%u tag_type=%u yaw=%.2f pitch=%.2f dist=%u tx=%d ty=%d tz=%d flags=%02X\r\n",
               frame.data.vision.seq,
               frame.data.vision.tag_id,
               frame.data.vision.tag_type,
               frame.data.vision.yaw_cdeg / 100.0f,
               frame.data.vision.pitch_cdeg / 100.0f,
               frame.data.vision.dist_mm,
               frame.data.vision.tx_mm,
               frame.data.vision.ty_mm,
               frame.data.vision.tz_mm,
               frame.data.vision.flags);
      }
    }

    if (HAL_GetTick() - vision_print_tick >= 1000U) {
      vision_print_tick = HAL_GetTick();
      MachineVision_GetStats(&stats);
      printf("VISION_STAT rx=%lu ok_v=%lu ok_c=%lu crc_err=%lu fmt_err=%lu ovf=%lu\r\n",
             stats.total_rx_bytes,
             stats.parsed_vision_frames,
             stats.parsed_cmd_frames,
             stats.crc_error_frames,
             stats.format_error_frames,
             stats.ring_overflow_bytes);
    }
  }
  /* USER CODE END StartVision_Task */
}

void StartMotion_Task(void *argument)
{
  /* USER CODE BEGIN StartMotion_Task */

  /* 初始化舵机 */
  Servo_Init();
  IMU_Init(); // 初始化IMU以接收数据
  osDelay(100);
  IMU_ZeroZAxis(); // 开启电源后，MPU6050清零
  osDelay(100);

  uint16_t last_servo_angle = 90;  /* 记录上一个有效的舵机角度 */
  const uint16_t servo_step = 2;    /* 固定步进角度：每个周期移动2度 */
  static uint8_t init_rotate_pd = 0; /* 用于连续转90°测试的 PD 控制器初始化标志 */
  static float last_yaw_err = 0.0f;   /* 上一次的偏航角误差，用于微分项计算 */
  static uint32_t climb_wall_align_start_tick = 0; /* 记录开始顶墙对齐的时间戳 */
  static uint8_t rotate_step = 0;    /* 记录完成了几次 90° 旋转 (0~3) */
  static float up_ir_values[4] = {0.0f}; /* 记录 4 个停顿位置的高位红外数值 */
  static float climb_target_angle = 0.0f; /* 登台阶段转向的目标角度 */
  static RobotState_e climb_next_state = ROBOT_FINISHED; /* 转向完成后的下一个状态 */
  static uint32_t climb_timer = 0;    /* 登台用计时器 */
  static int saved_D_smaller = 0;     /* 角落判定下，暂存数值较小的传感器方向 */

  /* 自适应软启动基准校准（防上电时手拿开的误差） */
  /* 给 Sensor_Task 充裕的通电稳定与采样等待时间，防止开机读取 0 盲值 */
  osDelay(1000);

  float sum_L = 0.0f;
  float sum_R = 0.0f;
  const int sample_cnt = 20;
  for (int i = 0; i < sample_cnt; i++)
  {
    osDelay(50); // 50ms x 20 = 1000ms 动态校准采样
    sum_L += IR_Distance_L;
    sum_R += IR_Distance_R;
  }
  float avg_L = sum_L / sample_cnt;
  float avg_R = sum_R / sample_cnt;

  float L_block_threshold   = 40.0f;  /* 30cm 内判定为手遮挡 */
  float R_block_threshold   = 40.0f;
  float L_release_threshold = 40.0f;  /* 40cm 外判定为手移开 */
  float R_release_threshold = 40.0f;

  printf("[SoftStart] Calibrated baselines - L: avg=%.1f, block=%.1f, release=%.1f\r\n", avg_L, L_block_threshold, L_release_threshold);
  printf("[SoftStart] Calibrated baselines - R: avg=%.1f, block=%.1f, release=%.1f\r\n", avg_R, R_block_threshold, R_release_threshold);

  /* Infinite loop */
  for(;;)
  {
    /* 视觉数据超时保护：如果处于调试模式下且超过500ms无视觉更新，重置目标为255 */
    if (is_vision_debug_mode > 0 && (HAL_GetTick() - last_vision_tick > 500U))
    {
      global_vision_target = 255;
    }

    /* 串口全程打印小车“在台上”或“在台下”，便于调试 */
    static uint32_t last_status_print_tick = 0;
    if (HAL_GetTick() - last_status_print_tick >= 500)
    {
      last_status_print_tick = HAL_GetTick();
      if (robot_state == ROBOT_RUNNING && onstage_confirmed == 1)
      {
        printf("[Status] 在台上\r\n");
      }
      else
      {
        printf("[Status] 在台下\r\n");
      }
    }

    /* 移除了底盘灰度渐变滤波与平复检测，改由高低区间与几何检测直接确诊 */

    /* 紧急控制检测（在循环最前部运行，无视当前状态，确保开启自愈、软启动或爬台阶等任何时期均可急停） */
    if (Control_IsOnline())
    {
      PC_ControlData_t ctrl = Control_GetData();

      /* 紧急停机：按下遥控器 B 键 (buttons & 2) 立即停止所有电机并锁死在 FINISHED 状态 */
      if (ctrl.buttons & 2)
      {
        robot_state = ROBOT_FINISHED;
        Motor_Control(0, 0);
        printf("已停止\r\n");
        last_buttons = ctrl.buttons;
        osDelay(20);
        continue;
      }

      /* 恢复状态：按下遥控器 X 键 (buttons & 4) 解除停机状态并恢复正常运行 */
      if (ctrl.buttons & 4)
      {
        if (robot_state == ROBOT_FINISHED)
        {
          robot_state = ROBOT_RUNNING;
        }
        printf("已恢复\r\n");
        last_buttons = ctrl.buttons;
        osDelay(20);
        continue;
      }
    }

    /* 如果处于自动登台的各种准备或冲刺状态，则完全接管常规控制流，执行独立的高频状态机 */
    if (robot_state != ROBOT_RUNNING)
    {
      /* 增加台下自动上台状态下的“直感台上检测”自愈：
         只在 ROBOT_SCANNING 状态，或者 ROBOT_CLIMBING_OFFSTAGE 状态且倒车爬行时间已超过 500ms 时起作用。
         可通过 4 路底盘灰度传感器，或几何开阔空间特征（红外测距）判定已在台上。 */
      uint8_t allow_onstage_detect = 0;
      if (robot_state == ROBOT_SCANNING)
      {
        allow_onstage_detect = 1;
      }
      else if (robot_state == ROBOT_CLIMBING_OFFSTAGE)
      {
        if (HAL_GetTick() - climb_start_tick >= 500U)
        {
          allow_onstage_detect = 1;
        }
      }

      if (allow_onstage_detect)
      {
        uint8_t low_grey_count = 0;
        if (Grey_Front < 180.0f) low_grey_count++;
        if (Grey_Back < 180.0f) low_grey_count++;
        if (Grey_Left < 180.0f) low_grey_count++;
        if (Grey_Right < 180.0f) low_grey_count++;

        uint8_t geometry_onstage = (IR_Distance_UP >= TOP_IR_THRESHOLD && IR_Distance_B >= 60.0f && (IR_Distance_L >= 50.0f || IR_Distance_R >= 50.0f));

        if (low_grey_count >= 3 || geometry_onstage)
        {
          Motor_Control(0, 0);
          robot_state = ROBOT_RUNNING;
          onstage_confirmed = 1;
          printf("[AutoClimb] Direct Onstage Auto-Recovery! %s confirm we are already on stage. State -> ROBOT_RUNNING\r\n",
                 (low_grey_count >= 3) ? "Underbody sensors" : "Geometry sensors (IR Dist)");
          osDelay(20);
          continue;
        }
      }
      switch (robot_state)
      {
        case ROBOT_WAITING:
        {
          /* 等待状态：停止电机 */
          Motor_Control(0, 0);

          /* 调试打印：每500ms打印一次当前阻挡检测状态 */
          static uint32_t last_wait_print = 0;
          if (HAL_GetTick() - last_wait_print >= 500)
          {
            last_wait_print = HAL_GetTick();
            printf("[SoftStart] WAITING. L_dist=%.1f (Thres=%.1f), R_dist=%.1f (Thres=%.1f)\r\n",
                   IR_Distance_L, L_block_threshold, IR_Distance_R, R_block_threshold);
          }

          /* 检测双手是否挡住左右红外传感器 */
          if (IR_Distance_L < L_block_threshold && IR_Distance_R < R_block_threshold)
          {
            soft_start_confirm++;
            if (soft_start_confirm >= SOFT_START_CONFIRM_CNT)
            {
              robot_state = ROBOT_ARMED;
              soft_start_confirm = 0;
              printf("[SoftStart] Ready! Release hands to launch. State -> ROBOT_ARMED\r\n");
            }
          }
          else
          {
            soft_start_confirm = 0;
          }
          break;
        }

        case ROBOT_ARMED:
        {
          /* 就绪状态：停止电机 */
          Motor_Control(0, 0);

          /* 调试打印：每500ms打印一次当前释放检测状态 */
          static uint32_t last_armed_print = 0;
          if (HAL_GetTick() - last_armed_print >= 500)
          {
            last_armed_print = HAL_GetTick();
            printf("[SoftStart] ARMED. L_dist=%.1f (Thres=%.1f), R_dist=%.1f (Thres=%.1f)\r\n",
                   IR_Distance_L, L_release_threshold, IR_Distance_R, R_release_threshold);

            /* 在就绪状态下，定时清零 Z 轴，确保释放瞬间 Yaw 接近绝对 0° */
            IMU_ZeroZAxis();
          }

          /* 检测左右红外距离是否都大于自适应松开距离 */
          if (IR_Distance_L > L_release_threshold && IR_Distance_R > R_release_threshold)
          {
            soft_release_confirm++;
            if (soft_release_confirm >= SOFT_START_CONFIRM_CNT)
            {
              robot_state = ROBOT_INIT_CLIMB;
              soft_release_confirm = 0;
              climb_start_tick = HAL_GetTick();
              target_angle_lock = 0.0f;          // 已经清零，目标设定为绝对 0.0°
              climb_pd_init = 0;                 // 重置 PD 控制器初始化标志
              printf("[SoftStart] Hands released! State -> ROBOT_INIT_CLIMB. Climbing up...\r\n");
            }
          }
          else
          {
            soft_release_confirm = 0;
          }
          break;
        }

        case ROBOT_INIT_CLIMB:
        {
          /* 初始登台冲刺：开环全速倒车，彻底禁用陀螺仪和速度渐变软启动，以获得最大初始扭矩和冲力 */
          Motor_Control(0, -100);

          /* 登台时间固定为 1.0 秒 (1000ms) */
          if (HAL_GetTick() - climb_start_tick >= 1000U)
          {
            /* 1S后立即刹车（闭环电机设为0速即为强力刹车） */
            Motor_Control(0, 0);
            osDelay(200); // 延时200ms以便让车体完全停稳消能

            /* 方案一：初始冲台结束后的“真假登台确诊” */
            uint8_t low_grey_count = 0;
            if (Grey_Front < 180.0f) low_grey_count++;
            if (Grey_Back < 180.0f) low_grey_count++;
            if (Grey_Left < 180.0f) low_grey_count++;
            if (Grey_Right < 180.0f) low_grey_count++;

            if (low_grey_count >= 3)
            {
              onstage_confirmed = 1; // 标记确切在台上，启动巡逻
              control_mode = 1;      // 开启自动模式
              robot_state = ROBOT_RUNNING;
              printf("[SoftClimb] Initial climb SUCCESS! Underbody sensors confirm we are on stage. State -> ROBOT_RUNNING (onstage).\r\n");
            }
            else
            {
              /* 没冲上去，判定在台下 */
              onstage_confirmed = 0;
              control_mode = 1;
              is_test_mode = 0;
              robot_state = ROBOT_TEST_ROTATE_PREPARE; // 退回270°扫描重新登台
              printf("[SoftClimb] Initial climb FAILED! Underbody sensors show we are still off-stage. Transition to ROBOT_TEST_ROTATE_PREPARE.\r\n");
            }
          }
          break;
        }

        case ROBOT_ALIGN_ORTHO:
        {
          /* 掉台就近角度对齐：计算最近的 0°, 90°, -90°, 180° / -180° 并原位旋转对齐 */
          float yaw_err = IMU_Data.Yaw - target_angle_lock;
          while (yaw_err > 180.0f)  yaw_err -= 360.0f;
          while (yaw_err < -180.0f) yaw_err += 360.0f;

          if (fabs(yaw_err) < 3.0f)
          {
            /* 转向完成：停止电机。既然已经用 Yaw 对准了，直接在此处根据上方红外判定方向，无需自转扫掠！ */
            Motor_Control(0, 0);
            osDelay(200);

            if (IR_Distance_UP >= TOP_IR_THRESHOLD)
            {
              /* 屁股（后部）面对的是台阶，铲子正对围栏，直接前冲对齐 */
              robot_state = ROBOT_SQUARING;
              squaring_start_tick = HAL_GetTick();
              printf("[OrthoAlign] Yaw %.1f aligned. Butt faces stage (correct). Squaring...\r\n", target_angle_lock);
            }
            else
            {
              /* 反了，屁股面对的是高围栏，需要原地调头 180 度 */
              float opp_yaw = target_angle_lock + 180.0f;
              while (opp_yaw > 180.0f)  opp_yaw -= 360.0f;
              while (opp_yaw < -180.0f) opp_yaw += 360.0f;
              target_angle_lock = opp_yaw;

              corner_type = 1;   /* 借用脱困逻辑变量 */
              corner_phase = 1;  /* 直接进入旋转阶段 */
              robot_state = ROBOT_CORNER_ESCAPE;
              printf("[OrthoAlign] Yaw %.1f aligned but reversed (UP_IR = %.1f). Adjusting 180 deg to %.1f...\r\n",
                     IMU_Data.Yaw, IR_Distance_UP, target_angle_lock);
            }
            init_rotate_pd = 0;
          }
          else
          {
            /* 转向 PD 控制 */
            if (init_rotate_pd == 0)
            {
              last_yaw_err = yaw_err;
              init_rotate_pd = 1;
            }
            float d_err = (yaw_err - last_yaw_err);
            last_yaw_err = yaw_err;

            float turn_speed = yaw_err * 0.8f + d_err * 7.5f;
            if (turn_speed > 18.0f)  turn_speed = 18.0f;
            if (turn_speed < -18.0f) turn_speed = -18.0f;

            if (fabs(yaw_err) > 5.0f)
            {
              if (turn_speed > 0.0f && turn_speed < 8.0f)  turn_speed = 8.0f;
              if (turn_speed < 0.0f && turn_speed > -8.0f) turn_speed = -8.0f;
            }
            Motor_Control((int16_t)turn_speed, 0);
          }
          break;
        }

        case ROBOT_LAUNCH_DECIDE:
        {
          is_test_mode = 0; /* 确认为官方正式登台流程 */
          /* 启动决策：利用 几何距离(不含前红外) + 底盘灰度 融合双重锁进行判定，达到 100% 绝对可靠性。
             - 台上特征：
               1. 灰度特征：底盘处于擂台之上，灰度反射率高，读数明显低于台下（擂台正中央及边缘灰度较低，任意底盘灰度传感器 < 180.0f）。
               2. 几何特征：由于擂台是 6cm 的凸起平台，水平测距传感器（左L、右R、后B）及上方红外会射向空中，读数极其开阔。
             - 台下特征：
               1. 灰度特征：身处纯黑地表通道，所有灰度传感器读数均较高（均 > 200.0f）。
               2. 几何特征：处于狭窄通道中（通道宽度仅约45cm），水平传感器必然会有多侧受限，无法满足开阔条件。
          */
          uint8_t low_grey_count = 0;
          if (Grey_Front < 180.0f)  low_grey_count++;
          if (Grey_Back < 180.0f)   low_grey_count++;
          if (Grey_Left < 180.0f)   low_grey_count++;
          if (Grey_Right < 180.0f)  low_grey_count++;

          uint8_t open_sides = 0;
          if (IR_Distance_L > 60.0f) open_sides++;
          if (IR_Distance_R > 60.0f) open_sides++;
          if (IR_Distance_B > 60.0f) open_sides++;

          uint8_t is_onstage = 0;
          uint8_t geometry_onstage = (IR_Distance_UP >= TOP_IR_THRESHOLD && IR_Distance_B >= 60.0f && (IR_Distance_L >= 50.0f || IR_Distance_R >= 50.0f));
          if (low_grey_count >= 3 || (low_grey_count >= 1 && open_sides >= 2) || geometry_onstage)
          {
            is_onstage = 1;
          }

          printf("[AutoClimb] Launch check details:\r\n");
          printf("  - Grey (F,B,L,R): %.1f, %.1f, %.1f, %.1f | low_grey_count = %d\r\n",
                 Grey_Front, Grey_Back, Grey_Left, Grey_Right, low_grey_count);
          printf("  - IR Dist (L,R,B): %.1f, %.1f, %.1f | open_sides = %d\r\n",
                 IR_Distance_L, IR_Distance_R, IR_Distance_B, open_sides);

          if (is_onstage)
          {
            /* 台上启动：直接静止不动 */
            robot_state = ROBOT_CLIMBING_ONSTAGE;
            climb_start_tick = HAL_GetTick();
            printf("[AutoClimb] Position: ON-STAGE. Platform detected, staying static. State -> ROBOT_CLIMBING_ONSTAGE\r\n");
          }
          else
          {
            /* 台下启动：进入台下自主扫描登台状态 */
            is_test_mode = 0;
            robot_state = ROBOT_TEST_ROTATE_PREPARE;
            printf("[AutoClimb] Position: OFF-STAGE. Initiating 270 deg scan... State -> ROBOT_TEST_ROTATE_PREPARE\r\n");
          }
          break;
        }

        case ROBOT_CLIMBING_ONSTAGE:
        {
          /* 台上启动：保持绝对静止 */
          Motor_Control(0, 0);
          robot_state = ROBOT_FINISHED;
          printf("[AutoClimb] On-stage static mode activated. State -> ROBOT_FINISHED.\r\n");
          break;
        }

        case ROBOT_SCANNING:
        {
          /* 台下自动寻向与对齐：无论如何，启动后先缓慢自转扫掠环境。
             利用通道极其狭窄（约45cm）的物理约束进行动态扫掠判定，彻底避开前红外测距(max=30cm)的物理量程限制！
          */

          /* 启动自转扫掠 */
          Motor_Control(SCAN_ROTATE_SPEED, 0);

          /* 1. 动态扫掠过程中，首先实时判定是否处于角落 (后方和左/右同时贴墙，不包含前方红外) */
          if (IR_Distance_B < 40.0f && IR_Distance_L < 40.0f)
          {
            /* 后左角 (B+L) */
            corner_type = 1;
            corner_phase = 0;
            corner_start_tick = HAL_GetTick();
            robot_state = ROBOT_CORNER_ESCAPE;
            Motor_Control(0, 0);
            printf("[AutoClimb] Corner detected during sweep: BACK-LEFT. Escaping...\r\n");
            break;
          }
          else if (IR_Distance_B < 40.0f && IR_Distance_R < 40.0f)
          {
            /* 后右角 (B+R) */
            corner_type = 2;
            corner_phase = 0;
            corner_start_tick = HAL_GetTick();
            robot_state = ROBOT_CORNER_ESCAPE;
            Motor_Control(0, 0);
            printf("[AutoClimb] Corner detected during sweep: BACK-RIGHT. Escaping...\r\n");
            break;
          }

          /* 2. 动态扫掠过程中，由原先的红外差值判定，重构为用 MPU6050 的 Yaw 轴对齐 */
          else
          {
            float yaw_div = IMU_Data.Yaw / 90.0f;
            int rounded_index = (yaw_div >= 0.0f) ? (int)(yaw_div + 0.5f) : (int)(yaw_div - 0.5f);
            float nearest_snap_yaw = (float)rounded_index * 90.0f;
            float snap_err = IMU_Data.Yaw - nearest_snap_yaw;
            while (snap_err > 180.0f)  snap_err -= 360.0f;
            while (snap_err < -180.0f) snap_err += 360.0f;

            if (fabs(snap_err) < 5.0f)
            {
              /* 必须检测到有侧向或后方墙壁，表明在通道中 */
              if (IR_Distance_B < 50.0f || IR_Distance_L < 50.0f || IR_Distance_R < 50.0f)
              {
                target_angle_lock = nearest_snap_yaw;

                if (IR_Distance_UP >= TOP_IR_THRESHOLD)
                {
                  /* 完美！屁股（后部）面对的是低台阶（射空），铲子（前部）正对高围栏。直接进入顶墙对齐！ */
                  robot_state = ROBOT_SQUARING;
                  squaring_start_tick = HAL_GetTick();
                  Motor_Control(0, 0);
                  printf("[AutoClimb] Sweep Yaw aligned to %.1f. Squaring...\r\n", target_angle_lock);
                }
                else
                {
                  /* 反了！屁股（后部）面对的是围栏高墙，车头（前部）正对低台阶。我们需要原地旋转 180 度！ */
                  float opp_yaw = target_angle_lock + 180.0f;
                  while (opp_yaw > 180.0f)  opp_yaw -= 360.0f;
                  while (opp_yaw < -180.0f) opp_yaw += 360.0f;
                  target_angle_lock = opp_yaw;

                  corner_type = 1;   /* 借用脱困逻辑变量 */
                  corner_phase = 1;  /* 直接进入旋转阶段 */
                  robot_state = ROBOT_CORNER_ESCAPE;
                  Motor_Control(0, 0);
                  printf("[AutoClimb] Sweep Yaw aligned to %.1f but reversed (UP_IR = %.1f). Adjusting 180 deg to %.1f...\r\n",
                         IMU_Data.Yaw, IR_Distance_UP, target_angle_lock);
                }
                break;
              }
            }
          }
          break;
        }

        case ROBOT_CORNER_ESCAPE:
        {
          if (corner_phase == 0)
          {
            /* 阶段 0：开环避障移动 */
            if (corner_type == 1 || corner_type == 2)
            {
              /* 后侧有墙，向前行驶避开 */
              Motor_Control(0, 30);
            }
            else
            {
              /* 备用兜底：前侧有墙，向后倒退避开 */
              Motor_Control(0, -30);
            }

            if (HAL_GetTick() - corner_start_tick >= CORNER_MOVE_MS)
            {
              Motor_Control(0, 0);
              corner_phase = 1;

              /* 计算精确且完美的 90° 的倍数转向目标角度，完全基于 Yaw=0° 的初始平行态 */
              if (corner_type == 1)      target_angle_lock = 90.0f;  /* 后左角：转至左转 90° 面向围栏 */
              else if (corner_type == 2) target_angle_lock = -90.0f; /* 后右角：转至右转 90° 面向围栏 */
              else                       target_angle_lock = 90.0f;

              printf("[AutoClimb] Corner move done. Next: turn to snapped Target Yaw: %.1f...\r\n", target_angle_lock);
            }
          }
          else
          {
            /* 阶段 1：使用陀螺仪反馈，原位旋转至完美的 90° 的倍数对准边缘 */
            float yaw_err = IMU_Data.Yaw - target_angle_lock;
            while (yaw_err > 180.0f)  yaw_err -= 360.0f;
            while (yaw_err < -180.0f) yaw_err += 360.0f;

            if (fabs(yaw_err) < 5.0f)
            {
              /* 转向完成：进入顶墙对齐状态 */
              Motor_Control(0, 0);
              robot_state = ROBOT_SQUARING;
              squaring_start_tick = HAL_GetTick();
              printf("[AutoClimb] Turn complete! Transition to ROBOT_SQUARING...\r\n");
            }
            else
            {
              /* 简单的比例控制旋转速度 */
              float turn_speed = yaw_err * 1.2f;
              if (turn_speed > 25.0f)  turn_speed = 25.0f;
              if (turn_speed < -25.0f) turn_speed = -25.0f;

              /* 设定转向死区，防止低速电机不转 */
              if (turn_speed > 0 && turn_speed < 12.0f)  turn_speed = 12.0f;
              if (turn_speed < 0 && turn_speed > -12.0f) turn_speed = -12.0f;

              Motor_Control((int16_t)turn_speed, 0);
            }
          }
          break;
        }

        case ROBOT_SQUARING:
        {
          /* 物理对齐：以 SQUARING_SPEED 向前顶墙，物理顶墙时间为固定的 1200ms */
          Motor_Control(0, SQUARING_SPEED);

          if (HAL_GetTick() - squaring_start_tick >= SQUARING_DURATION_MS)
          {
            /* 停止电机，等待 100ms 以实现物理惯性静止，然后清零 IMU 偏航角 */
            Motor_Control(0, 0);
            osDelay(100);

            IMU_ZeroZAxis();
            osDelay(100); /* 等待零偏写入完成 */

            target_angle_lock = 0.0f; /* 锁定完美的 0° 倒退直走 */
            climb_pd_init = 0;        /* 清零 PD 控制器初始化标志 */
            robot_state = ROBOT_CLIMBING_OFFSTAGE;
            robot_state = ROBOT_CLIMBING_OFFSTAGE;
            climb_start_tick = HAL_GetTick();
            printf("[AutoClimb] Squaring complete! Yaw Z-axis reset to 0. Starting closed-loop climb...\r\n");
          }
          break;
        }

        case ROBOT_CLIMBING_OFFSTAGE:
        {
          /* 台下闭环登台：全速倒车 + 陀螺仪锁角PD纠偏（闭环控制） */
          float yaw_err = IMU_Data.Yaw - target_angle_lock;
          while (yaw_err > 180.0f)  yaw_err -= 360.0f;
          while (yaw_err < -180.0f) yaw_err += 360.0f;

          if (climb_pd_init == 0)
          {
            last_yaw_err = yaw_err;
            climb_pd_init = 1;
          }

          /* 计算微分项 */
          float d_err = (yaw_err - last_yaw_err) / 0.020f; /* 20ms 的刷新周期 */
          last_yaw_err = yaw_err;

          /* PD 纠偏控制输出 */
          float heading_correction = yaw_err * HEADING_KP + d_err * HEADING_KD;
          if (heading_correction > 30.0f)  heading_correction = 30.0f;
          if (heading_correction < -30.0f) heading_correction = -30.0f;

          /* 闭环负反馈进行纠偏：对于反相安装的硬件，使用 -heading_correction 纠错。直接使用全速 CLIMB_SPEED，无软启动 */
          Motor_Control((int16_t)-heading_correction, CLIMB_SPEED);

          uint32_t elapsed = HAL_GetTick() - climb_start_tick;

          /* 登台判定：后退冲台固定 1 秒 (CLIMB_OFFSTAGE_TIMEOUT_MS=1000ms)，到时立即刹车
             - 测试模式：刹车后进入 ROBOT_FINISHED 静止
             - 正式模式：刹车后进入 ROBOT_RUNNING 开始台上战斗 */
          if (elapsed >= CLIMB_OFFSTAGE_TIMEOUT_MS)
          {
            Motor_Control(0, 0);
            if (is_test_mode)
            {
              robot_state = ROBOT_FINISHED;
              printf("[TestClimb] Climb complete! Reversed for %lums. State -> ROBOT_FINISHED.\r\n", elapsed);
            }
            else
            {
              onstage_confirmed = 0;
              control_mode = 1; // 自动进入自动控制模式
              robot_state = ROBOT_RUNNING;
              printf("[AutoClimb] Climb complete! Reversed for %dms then braked. State -> ROBOT_RUNNING.\r\n", CLIMB_OFFSTAGE_TIMEOUT_MS);
            }
          }
          break;
        }

        case ROBOT_FINISHED:
        {
          /* 登台完成或台上待机：保持绝对静止 */
          Motor_Control(0, 0);
          break;
        }

        case ROBOT_TEST_ROTATE_PREPARE:
        {
          /* 1. 停止小车电机，准备校准 */
          Motor_Control(0, 0);

          /* 2. 发送指令重置 Z 轴角度（偏航角） */
          IMU_ZeroZAxis();

          /* 3. 在任务上下文中安全地等待最多 500ms 直到读取到真实的零偏数据 */
          uint32_t wait_start = HAL_GetTick();
          while (HAL_GetTick() - wait_start < 500)
          {
            osDelay(20);
            if (fabs(IMU_Data.Yaw) < 1.0f)
            {
              break;
            }
          }

          /* 4. 开始和每次停顿的时候记录后方靠上的传感器数值 (S0) */
          up_ir_values[0] = IR_Distance_UP;
          rotate_step = 0;

          /* 5. 初始化转向参数并跳转到 90° 旋转测试状态（本车逆时针/左转会导致偏航角 Yaw 增加） */
          target_angle_lock = 90.0f;
          init_rotate_pd = 0; /* 标志位重置 */
          robot_state = ROBOT_TEST_ROTATE_90;

          printf("[TestRotate] Z-axis zeroed. Target locked to 90.0. Start IR: S0=%.1f. Entering ROBOT_TEST_ROTATE_90 loop...\r\n", up_ir_values[0]);
          break;
        }

        case ROBOT_TEST_ROTATE_90:
        {
          /* 逆时针转动 90° */
          float yaw_err = IMU_Data.Yaw - target_angle_lock;
          while (yaw_err > 180.0f)  yaw_err -= 360.0f;
          while (yaw_err < -180.0f) yaw_err += 360.0f;

          /* 降低实时调试打印频率至 300ms 一次 */
          static uint32_t last_print_tick = 0;
          if (HAL_GetTick() - last_print_tick >= 300)
          {
            last_print_tick = HAL_GetTick();
            printf("[TestRotate] Step: %d, Target: %.1f, Yaw: %.1f, Err: %.1f\r\n", rotate_step, target_angle_lock, IMU_Data.Yaw, yaw_err);
          }

          /* 缩紧死区为更精确的 3.0° */
          if (fabs(yaw_err) < 3.0f)
          {
            /* 达到当前目标角度，停顿 0.3s (300ms) */
            Motor_Control(0, 0);
            osDelay(300);

            /* 每次停顿的时候记录后方靠上的传感器数值 */
            rotate_step++;
            if (rotate_step <= 3)
            {
              up_ir_values[rotate_step] = IR_Distance_UP;
              printf("[TestRotate] Stop recorded: S%d=%.1f\r\n", rotate_step, up_ir_values[rotate_step]);
            }

            /* 如果转完了 270°（即 rotate_step 达到 3），进行边缘/角落判定，并启动对应登台逻辑 */
            if (rotate_step >= 3)
            {
              uint8_t blocked[4] = {0};
              int blocked_count = 0;
              for (int i = 0; i < 4; i++)
              {
                if (up_ir_values[i] < 95.0f)
                {
                  blocked[i] = 1;
                  blocked_count++;
                }
              }

              // 首尾（index 0 和 3）也算相邻，环形相邻检查
              uint8_t has_adjacent = (blocked[0] && blocked[1]) ||
                                     (blocked[1] && blocked[2]) ||
                                     (blocked[2] && blocked[3]) ||
                                     (blocked[3] && blocked[0]);

              printf("[TestRotate] Scan complete! S0=%.1f, S1=%.1f, S2=%.1f, S3=%.1f\r\n",
                     up_ir_values[0], up_ir_values[1], up_ir_values[2], up_ir_values[3]);
              printf("[TestRotate] Blocked status: [%d, %d, %d, %d] (count=%d, has_adj=%d)\r\n",
                     blocked[0], blocked[1], blocked[2], blocked[3], blocked_count, has_adjacent);

              if (has_adjacent)
              {
                printf("在角落\r\n");

                // 寻找具有最小传感器数值之和的相邻被阻挡方向对，以确保在噪声干扰或多向阻挡时精准定位真实墙面
                int idx1 = -1, idx2 = -1;
                float min_sum = 9999.0f;

                for (int i = 0; i < 4; i++)
                {
                  int next_i = (i + 1) % 4;
                  if (blocked[i] && blocked[next_i])
                  {
                    float sum = up_ir_values[i] + up_ir_values[next_i];
                    if (sum < min_sum)
                    {
                      min_sum = sum;
                      idx1 = i;
                      idx2 = next_i;
                    }
                  }
                }

                if (idx1 != -1 && idx2 != -1)
                {
                  // 比较这两个方向上靠上的传感器数值大小
                  int D_larger = (up_ir_values[idx1] > up_ir_values[idx2]) ? idx1 : idx2;
                  int D_smaller = (up_ir_values[idx1] > up_ir_values[idx2]) ? idx2 : idx1;

                  saved_D_smaller = D_smaller; // 暂存较小值方向

                  // 计算较大方向的物理角度（由于探测时车尾朝墙，此方向即为车头朝向开阔侧的方向）
                  float angle_larger = D_larger * 90.0f;
                  while (angle_larger > 180.0f) angle_larger -= 360.0f;
                  while (angle_larger < -180.0f) angle_larger += 360.0f;

                  climb_target_angle = angle_larger;
                  climb_next_state = ROBOT_CLIMB_FORWARD_UNTIL_UP_IR;
                  robot_state = ROBOT_CLIMB_ROTATE_TO_DIR;
                  init_rotate_pd = 0;

                  printf("[TestClimb] Corner detected! Selected adjacent pair %d and %d. Turning to D_larger=%d (angle=%.1f), saved D_smaller=%d\r\n",
                         idx1, idx2, D_larger, climb_target_angle, saved_D_smaller);
                }
                else
                {
                  robot_state = ROBOT_FINISHED;
                }
              }
              else if (blocked_count == 1)
              {
                printf("在边缘\r\n");

                // 找出阻碍的那一个方向
                int D_blocked = 0;
                for (int i = 0; i < 4; i++)
                {
                  if (blocked[i]) { D_blocked = i; break; }
                }

                // 计算相反方向物理角度 (D_blocked * 90 + 180)
                float opp_angle = (D_blocked * 90.0f) + 180.0f;
                while (opp_angle > 180.0f) opp_angle -= 360.0f;
                while (opp_angle < -180.0f) opp_angle += 360.0f;

                climb_target_angle = opp_angle;
                climb_next_state = ROBOT_CLIMB_FORWARD_UNTIL_WALL;
                robot_state = ROBOT_CLIMB_ROTATE_TO_DIR;
                init_rotate_pd = 0;

                printf("[TestClimb] Edge detected! Turning to opposite of D_blocked=%d (opp_angle=%.1f) to face fence\r\n",
                       D_blocked, climb_target_angle);
              }
              else
              {
                printf("不在边缘且不在角落 (障碍数: %d)，小车重新回到台上运行状态以自愈\r\n", blocked_count);
                robot_state = ROBOT_RUNNING;
              }
            }
            else
            {
              /* 设定下一个逆时针转动 90° 的目标角（逆时针/左转使 Yaw 增加，所以每次加上 90°） */
              target_angle_lock += 90.0f;
              while (target_angle_lock > 180.0f)  target_angle_lock -= 360.0f;
              while (target_angle_lock < -180.0f) target_angle_lock += 360.0f;

              /* 重新初始化 PD 控制器的基准值，防止目标突变产生错误的微分冲击 */
              init_rotate_pd = 0;

              printf("[TestRotate] Moving to Next Target Yaw: %.1f\r\n", target_angle_lock);
            }
          }
          else
          {
            /* 引入 PD 控制以获得阻尼效果 */
            if (init_rotate_pd == 0)
            {
              last_yaw_err = yaw_err;
              init_rotate_pd = 1;
            }
            float d_err = (yaw_err - last_yaw_err);
            last_yaw_err = yaw_err;

            float turn_speed = yaw_err * 0.8f + d_err * 7.5f;

            /* 限制最大输出转速，防止电机满载滑行过冲 */
            if (turn_speed > 18.0f)  turn_speed = 18.0f;
            if (turn_speed < -18.0f) turn_speed = -18.0f;

            /* 误差限幅控制 */
            if (fabs(yaw_err) > 5.0f)
            {
              if (turn_speed > 0.0f && turn_speed < 8.0f)  turn_speed = 8.0f;
              if (turn_speed < 0.0f && turn_speed > -8.0f) turn_speed = -8.0f;
            }

            Motor_Control((int16_t)turn_speed, 0);
          }
          break;
        }

        case ROBOT_CLIMB_ROTATE_TO_DIR:
        {
          float yaw_err = IMU_Data.Yaw - climb_target_angle;
          while (yaw_err > 180.0f)  yaw_err -= 360.0f;
          while (yaw_err < -180.0f) yaw_err += 360.0f;

          if (fabs(yaw_err) < 3.0f)
          {
            /* 转向完成：停止电机，并切换到下一阶段 */
            Motor_Control(0, 0);
            osDelay(200);
            init_rotate_pd = 0; // 重置 PD 标志
            robot_state = climb_next_state;
            if (climb_next_state == ROBOT_SQUARING)
            {
              squaring_start_tick = HAL_GetTick();
            }
            if (climb_next_state == ROBOT_CLIMB_FORWARD_UNTIL_WALL || climb_next_state == ROBOT_CLIMB_FORWARD_UNTIL_UP_IR || climb_next_state == ROBOT_TEST_ATTACK_MOVE)
            {
              climb_wall_align_start_tick = HAL_GetTick();
            }
            printf("[TestClimb] Rotation to %.1f complete. Next state: %d\r\n", climb_target_angle, climb_next_state);
          }
          else
          {
            /* 转向 PD 控制 */
            if (init_rotate_pd == 0)
            {
              last_yaw_err = yaw_err;
              init_rotate_pd = 1;
            }
            float d_err = (yaw_err - last_yaw_err);
            last_yaw_err = yaw_err;

            float turn_speed = yaw_err * 0.8f + d_err * 7.5f;
            if (turn_speed > 18.0f)  turn_speed = 18.0f;
            if (turn_speed < -18.0f) turn_speed = -18.0f;

            if (fabs(yaw_err) > 5.0f)
            {
              if (turn_speed > 0.0f && turn_speed < 8.0f)  turn_speed = 8.0f;
              if (turn_speed < 0.0f && turn_speed > -8.0f) turn_speed = -8.0f;
            }
            Motor_Control((int16_t)turn_speed, 0);
          }
          break;
        }

        case ROBOT_CLIMB_FORWARD_UNTIL_UP_IR:
        {
          /* 前进避开角落障碍：直行直到后上方红外距离大于 110.0f */
          Motor_Control(0, 25);

          uint32_t elapsed_escape = HAL_GetTick() - climb_wall_align_start_tick;
          if (IR_Distance_UP > 110.0f || elapsed_escape >= 2500U)
          {
            /* 成功越过，停止并准备转弯到 D_smaller 的相反方向 */
            Motor_Control(0, 0);
            osDelay(200);

            float opposite_smaller = (saved_D_smaller * 90.0f) + 180.0f;
            while (opposite_smaller > 180.0f) opposite_smaller -= 360.0f;
            while (opposite_smaller < -180.0f) opposite_smaller += 360.0f;

            climb_target_angle = opposite_smaller;
            climb_next_state = ROBOT_CLIMB_FORWARD_UNTIL_WALL;
            robot_state = ROBOT_CLIMB_ROTATE_TO_DIR;
            init_rotate_pd = 0;

            printf("[TestClimb] Corner escape forward complete (UP_IR=%.1f, elapsed=%lums). Next: turn to opposite of D_smaller (%.1f) and move forward until wall\r\n",
                   IR_Distance_UP, elapsed_escape, climb_target_angle);
          }
          break;
        }

        case ROBOT_CLIMB_FORWARD_UNTIL_WALL:
        {
          /* 向前前行开路 */
          Motor_Control(0, 25);

          uint32_t elapsed_align = HAL_GetTick() - climb_wall_align_start_tick;

          /* 依据图片逻辑：前方红外测距大于 48 或者后方红外测距大于 60，启动 1 秒倒计时（增加 2500ms 超时） */
          if (IR_Distance_F > 48.0f || IR_Distance_B > 60.0f || elapsed_align >= 2500U)
          {
            /* 条件触发，开启 1 秒延时 */
            climb_timer = HAL_GetTick();
            robot_state = ROBOT_CLIMB_FORWARD_DELAY;
            printf("[TestClimb] Wall condition met (F=%.1f, B=%.1f, elapsed=%lums). Starting 1s forward delay...\r\n",
                   IR_Distance_F, IR_Distance_B, elapsed_align);
          }
          break;
        }

        case ROBOT_CLIMB_FORWARD_DELAY:
        {
          /* 继续前行 1 秒 */
          Motor_Control(0, 25);

          if (HAL_GetTick() - climb_timer >= 1000U)
          {
            /* 1秒到，全速向后倒退冲上擂台 */
            climb_timer = HAL_GetTick();
            robot_state = ROBOT_CLIMB_BACKWARD_FAST;
            printf("[TestClimb] Delay complete. Launching full speed backward for 1s...\r\n");
          }
          break;
        }

        case ROBOT_CLIMB_BACKWARD_FAST:
        {
          /* 全速向后冲台 */
          Motor_Control(0, -100);

          if (HAL_GetTick() - climb_timer >= 1000U)
          {
            /* 登台结束，刹车停止，返回台上战斗模式 */
            Motor_Control(0, 0);
            control_mode = 1; // 自动进入自动控制模式
            robot_state = ROBOT_RUNNING;
            onstage_confirmed = 0;
            printf("[AutoClimb] Onstage complete! Robot back on stage. State -> ROBOT_RUNNING\r\n");
          }
          break;
        }

        case ROBOT_TEST_ATTACK_PREPARE:
        {
          /* 1. 停止电机 */
          Motor_Control(0, 0);
          /* 2. MPU6050 清零 */
          IMU_ZeroZAxis();

          /* 3. 在任务上下文中安全地等待最多 500ms 直到读取到真实的零偏数据 */
          uint32_t wait_start = HAL_GetTick();
          while (HAL_GetTick() - wait_start < 500)
          {
            osDelay(20);
            if (fabs(IMU_Data.Yaw) < 1.0f)
            {
              break;
            }
          }

          printf("[TestAttack] MPU6050 zeroed. Entering ROBOT_TEST_ATTACK_RUNNING...\r\n");
          robot_state = ROBOT_TEST_ATTACK_RUNNING;
          break;
        }

        case ROBOT_TEST_ATTACK_RUNNING:
        {
          /* 获取 IR 距离，依据自主识别敌人步骤计算转角 */
          float dist[8];
          dist[0] = ir_distance[0]; // 前方
          dist[1] = ir_distance[1]; // 左前
          dist[2] = ir_distance[8]; // 左侧 (交换后)
          dist[3] = ir_distance[3]; // 左后
          dist[4] = ir_distance[5]; // 后方
          dist[5] = ir_distance[4]; // 右后
          dist[6] = ir_distance[6]; // 右侧 (交换后)
          dist[7] = ir_distance[2]; // 右前

          /* 判断各方向是否触发，前方<20，其余<50 */
          int trig[8];
          for(int i = 0; i < 8; i++) {
              if (i == 0) trig[i] = (dist[i] < 20.0f) ? 1 : 0;
              else trig[i] = (dist[i] < 50.0f) ? 1 : 0;
          }

          int match_3 = -1;
          for(int i = 0; i < 8; i++) {
              int prev = (i + 7) % 8;
              int next = (i + 1) % 8;
              if (trig[prev] && trig[i] && trig[next]) {
                  match_3 = i;
                  break;
              }
          }

          int match_2_1 = -1, match_2_2 = -1;
          if (match_3 == -1) {
              for(int i = 0; i < 8; i++) {
                  int next = (i + 1) % 8;
                  if (trig[i] && trig[next]) {
                      match_2_1 = i;
                      match_2_2 = next;
                      break;
                  }
              }
          }

          int match_1 = -1;
          if (match_3 == -1 && match_2_1 == -1) {
              for(int i = 0; i < 8; i++) {
                  if (trig[i]) {
                      match_1 = i;
                      break;
                  }
              }
          }

          float t_angle = 0.0f;
          int found = 0;

          if (match_3 != -1) {
              t_angle = match_3 * 45.0f;
              found = 1;
              printf("[TestAttack] 3 adjacent found at index %d\r\n", match_3);
          } else if (match_2_1 != -1) {
              if (match_2_1 == 7 && match_2_2 == 0) {
                  t_angle = 337.5f; /* (-45+0)/2 = -22.5 => 337.5 */
              } else {
                  t_angle = (match_2_1 + match_2_2) * 45.0f / 2.0f;
              }
              found = 1;
              printf("[TestAttack] 2 adjacent found at %d, %d\r\n", match_2_1, match_2_2);
          } else if (match_1 != -1) {
              t_angle = match_1 * 45.0f;
              found = 1;
              printf("[TestAttack] Single target found at index %d\r\n", match_1);
          }

          if (found) {
              /* 角度标准化到 -180 ~ 180 */
              while (t_angle > 180.0f) t_angle -= 360.0f;
              while (t_angle < -180.0f) t_angle += 360.0f;

              if (fabs(t_angle) < 5.0f) { // 直行
                 robot_state = ROBOT_TEST_ATTACK_MOVE;
                 climb_wall_align_start_tick = HAL_GetTick();
                 printf("[TestAttack] Target is front. Moving immediately...\r\n");
              } else {
                 climb_target_angle = t_angle;
                 climb_next_state = ROBOT_TEST_ATTACK_MOVE;
                 robot_state = ROBOT_CLIMB_ROTATE_TO_DIR;
                 init_rotate_pd = 0;
                 printf("[TestAttack] Turning to %.1f...\r\n", climb_target_angle);
              }
          }
          break;
        }

        case ROBOT_TEST_ATTACK_MOVE:
        {
          /* 向前移动0.5S */
          Motor_Control(0, 40); /* 假设速度设为40 */

          if (HAL_GetTick() - climb_wall_align_start_tick >= 500U)
          {
            /* 0.5s时间到 */
            Motor_Control(0, 0);
            robot_state = ROBOT_FINISHED;
            printf("[TestAttack] Move complete. Test attack finished.\r\n");
          }
          break;
        }

        case ROBOT_FIGHT_ATTACK_MOVE:
        {
          /* 实战冲击追击状态：以正常巡台速度向敌人方向行驶，并在前进中实时微调转向 */

          /* 获取 IR 距离，依据自主识别敌人步骤计算转角 */
          float dist[8];
          dist[0] = ir_distance[0]; // 前方
          dist[1] = ir_distance[1]; // 左前
          dist[2] = ir_distance[8]; // 左侧 (交换后)
          dist[3] = ir_distance[3]; // 左后
          dist[4] = ir_distance[5]; // 后方
          dist[5] = ir_distance[4]; // 右后
          dist[6] = ir_distance[6]; // 右侧 (交换后)
          dist[7] = ir_distance[2]; // 右前

          /* 判断各方向是否触发，前方 < 20.0f，其余 < 50.0f */
          int trig[8];
          for(int i = 0; i < 8; i++) {
              if (i == 0) trig[i] = (dist[i] < 20.0f) ? 1 : 0;
              else trig[i] = (dist[i] < 50.0f) ? 1 : 0;
          }

          int match_3 = -1;
          for(int i = 0; i < 8; i++) {
              int prev = (i + 7) % 8;
              int next = (i + 1) % 8;
              if (trig[prev] && trig[i] && trig[next]) {
                  match_3 = i;
                  break;
              }
          }

          int match_2_1 = -1, match_2_2 = -1;
          if (match_3 == -1) {
              for(int i = 0; i < 8; i++) {
                  int next = (i + 1) % 8;
                  if (trig[i] && trig[next]) {
                      match_2_1 = i;
                      match_2_2 = next;
                      break;
                  }
              }
          }

          int match_1 = -1;
          if (match_3 == -1 && match_2_1 == -1) {
              for(int i = 0; i < 8; i++) {
                  if (trig[i]) {
                      match_1 = i;
                      break;
                  }
              }
          }

          float t_angle = 0.0f;
          int found = 0;

          if (match_3 != -1) {
              t_angle = match_3 * 45.0f;
              found = 1;
          } else if (match_2_1 != -1) {
              if (match_2_1 == 7 && match_2_2 == 0) {
                  t_angle = -22.5f;
              } else {
                  t_angle = (match_2_1 + match_2_2) * 45.0f / 2.0f;
              }
              found = 1;
          } else if (match_1 != -1) {
              t_angle = match_1 * 45.0f;
              found = 1;
          }

          float turn_speed = 0.0f;
          if (found) {
              /* 角度标准化到 -180 ~ 180 */
              while (t_angle > 180.0f) t_angle -= 360.0f;
              while (t_angle < -180.0f) t_angle += 360.0f;

              static uint8_t re_align_filter = 0;
              if (fabs(t_angle) > 60.0f) {
                  re_align_filter++;
                  if (re_align_filter >= 4) {
                      /* 敌人偏移角度过大（偏到侧方或后方），停止向前，重新原地自转对齐 */
                      climb_target_angle = IMU_Data.Yaw + t_angle;
                      while (climb_target_angle > 180.0f)  climb_target_angle -= 360.0f;
                      while (climb_target_angle < -180.0f) climb_target_angle += 360.0f;

                      climb_next_state = ROBOT_FIGHT_ATTACK_MOVE;
                      robot_state = ROBOT_CLIMB_ROTATE_TO_DIR;
                      init_rotate_pd = 0;
                      Motor_Control(0, 0);
                      printf("[FightAttack] Enemy moved to side/behind (%.1f). Re-aligning...\r\n", t_angle);
                      re_align_filter = 0;
                      break; // 跳出当前 state 逻辑
                  }
              } else {
                  re_align_filter = 0;
                  /* 敌人在前方扇区内，计算转向速度（正值左转，负值右转） */
                  float Kp_track = 0.3f;
                  turn_speed = -t_angle * Kp_track;
                  if (turn_speed > 15.0f)  turn_speed = 15.0f;
                  if (turn_speed < -15.0f) turn_speed = -15.0f;
              }
          }

          /* 融合前行速度（正常巡台速度 18）与转向速度 */
          Motor_Control((int16_t)turn_speed, 18);

          /* 实时检测边缘：一旦有一侧检测到边缘值，立即制动、退后、转身，重回巡台 */
          if (Motion_IsEdgeRisk(laser_dist_1, laser_dist_2, Grey_Front))
          {
            printf("[FightAttack] Edge detected (Laser1: %d, Laser2: %d). Canceling attack, directional escape...\r\n", laser_dist_1, laser_dist_2);
            Motion_EscapeEdge(laser_dist_1, laser_dist_2, Grey_Front, Grey_Left, Grey_Right, Grey_Back);
            robot_state = ROBOT_RUNNING;
            printf("[FightAttack] Edge escape complete. Resuming patrol...\r\n");
            break;

            /* 1. 强力反向制动 80ms 快速消能，随后后退 150ms（后退中若后灰度检测到边缘则停止） */
            Motor_Control(0, -60);
            osDelay(80);
            Motor_Control(0, -18);
            for (int i = 0; i < 15; i++) {
                if (Grey_Back > 250.0f) break;
                osDelay(10);
            }

            /* 2. 转向避让：降低转弯速度（-60 -> -35），转向时间 450ms */
            if (laser_dist_1 > 260 && laser_dist_2 <= 260) {
              Motor_Control(-35, 0); // 左侧偏离，向右转
            } else if (laser_dist_1 <= 260 && laser_dist_2 > 260) {
              Motor_Control(35, 0);  // 右侧偏离，向左转
            } else {
              Motor_Control(-35, 0); // 双侧或异常，默认右转
            }
            osDelay(450);

            /* 3. 停止转向 */

            /* 4. 重置状态为 ROBOT_RUNNING，恢复常规巡台 */
          }
          break;
        }

        default:
          break;
      }

      /* 在自主登台及软启动非运行状态下，拦截常规控制，保持 20ms 的刷新周期 */
      osDelay(20);
      continue;
    }

    /* ========== ROBOT_RUNNING 台上运行时的确认与掉台检测 ========== */
    if (robot_state == ROBOT_RUNNING && is_test_mode == 0)
    {
      static uint32_t onstage_settle_start_tick = 0;

      /* 10秒卡死及掉台监测历史数据变量声明 */
      static float yaw_hist[10] = {0.0f};
      static float ir_f_hist[10] = {0.0f};
      static float grey_hist[4][10] = {0};
      static uint8_t hist_count = 0;
      static uint32_t last_hist_tick = 0;

      if (onstage_settle_start_tick == 0)
      {
        onstage_settle_start_tick = HAL_GetTick();
        printf("[FallDetection] onstage running! Settle timer started (1s).\r\n");
      }

      /* 10秒无动作卡死自愈监测 */
      if (HAL_GetTick() - last_hist_tick >= 1000U)
      {
        last_hist_tick = HAL_GetTick();

        // 移动历史窗口
        for (int i = 9; i > 0; i--)
        {
          yaw_hist[i] = yaw_hist[i-1];
          ir_f_hist[i] = ir_f_hist[i-1];
          for (int j = 0; j < 4; j++)
          {
            grey_hist[j][i] = grey_hist[j][i-1];
          }
        }

        // 插入最新采样
        yaw_hist[0] = IMU_Data.Yaw;
        ir_f_hist[0] = IR_Distance_F;
        grey_hist[0][0] = Grey_Front;
        grey_hist[1][0] = Grey_Back;
        grey_hist[2][0] = Grey_Left;
        grey_hist[3][0] = Grey_Right;

        if (hist_count < 10)
        {
          hist_count++;
        }

        if (hist_count >= 10)
        {
          float y_min = yaw_hist[0], y_max = yaw_hist[0];
          float ir_min = ir_f_hist[0], ir_max = ir_f_hist[0];
          float g_min[4], g_max[4];
          for (int j = 0; j < 4; j++)
          {
            g_min[j] = grey_hist[j][0];
            g_max[j] = grey_hist[j][0];
          }

          for (int i = 1; i < 10; i++)
          {
            if (yaw_hist[i] < y_min) y_min = yaw_hist[i];
            if (yaw_hist[i] > y_max) y_max = yaw_hist[i];

            if (ir_f_hist[i] < ir_min) ir_min = ir_f_hist[i];
            if (ir_f_hist[i] > ir_max) ir_max = ir_f_hist[i];

            for (int j = 0; j < 4; j++)
            {
              if (grey_hist[j][i] < g_min[j]) g_min[j] = grey_hist[j][i];
              if (grey_hist[j][i] > g_max[j]) g_max[j] = grey_hist[j][i];
            }
          }

          float yaw_span = y_max - y_min;
          float ir_span = ir_max - ir_min;
          uint8_t grey_stable = 1;
          for (int j = 0; j < 4; j++)
          {
            if (g_max[j] - g_min[j] >= 12.0f)
            {
              grey_stable = 0;
              break;
            }
          }

          /* 若偏航角、前红外测距及4路底盘灰度均高度稳定波动，判定卡死或掉台 */
          if (yaw_span < 10.0f && ir_span < 4.0f && grey_stable)
          {
            Motor_Control(0, 0);

            float yaw_div = IMU_Data.Yaw / 90.0f;
            int rounded_index = (yaw_div >= 0.0f) ? (int)(yaw_div + 0.5f) : (int)(yaw_div - 0.5f);
            target_angle_lock = (float)rounded_index * 90.0f;
            while (target_angle_lock > 180.0f)  target_angle_lock -= 360.0f;
            while (target_angle_lock < -180.0f) target_angle_lock += 360.0f;

            hist_count = 0;
            onstage_settle_start_tick = 0;
            is_test_mode = 0;
            robot_state = ROBOT_TEST_ROTATE_PREPARE;
            printf("[StuckDetection] Stuck for 10s detected (Yaw span=%.1f, IR span=%.1f). Forcing 270 deg scan to recover...\r\n", yaw_span, ir_span);
            osDelay(20);
            continue;
          }
        }
      }

      /* 阶段 3：已确定在台上并稳住 1s 后，开启实时掉台检测 */
      if (HAL_GetTick() - onstage_settle_start_tick >= 1000U)
      {
        /* 方案二：直感掉台检测（无 IMU 倾斜触发的平滑滑落） */
        uint8_t high_grey_count = 0;
        if (Grey_Front > 190.0f) high_grey_count++;
        if (Grey_Back > 190.0f)  high_grey_count++;
        if (Grey_Left > 190.0f)  high_grey_count++;
        if (Grey_Right > 190.0f) high_grey_count++;

        uint8_t open_sides = 0;
        if (IR_Distance_L > 60.0f) open_sides++;
        if (IR_Distance_R > 60.0f) open_sides++;
        if (IR_Distance_B > 60.0f) open_sides++;

        static uint32_t direct_fall_timer = 0;
        uint8_t geometry_onstage = (IR_Distance_UP >= TOP_IR_THRESHOLD && IR_Distance_B >= 60.0f && (IR_Distance_L >= 50.0f || IR_Distance_R >= 50.0f));
        if (high_grey_count >= 3 && !geometry_onstage)
        {
          if (direct_fall_timer == 0)
          {
            direct_fall_timer = HAL_GetTick();
          }
          else if (HAL_GetTick() - direct_fall_timer >= 500U)
          {
            Motor_Control(0, 0);

            float yaw_div = IMU_Data.Yaw / 90.0f;
            int rounded_index = (yaw_div >= 0.0f) ? (int)(yaw_div + 0.5f) : (int)(yaw_div - 0.5f);
            target_angle_lock = (float)rounded_index * 90.0f;
            while (target_angle_lock > 180.0f)  target_angle_lock -= 360.0f;
            while (target_angle_lock < -180.0f) target_angle_lock += 360.0f;

            direct_fall_timer = 0;
            onstage_settle_start_tick = 0;
            is_test_mode = 0;
            robot_state = ROBOT_TEST_ROTATE_PREPARE;
            printf("[FallDetection] Direct Fall CONFIRMED (Grey >= 3 > 190 && !geometry_onstage for 500ms)! Transition to ROBOT_TEST_ROTATE_PREPARE...\r\n");
            osDelay(20);
            continue;
          }
        }
        else
        {
          direct_fall_timer = 0;
        }
      }
    }

    /* ========== 台下/未确认台上时的初始与重新登台检测 ========== */
    if (onstage_confirmed == 0 && robot_state == ROBOT_RUNNING && control_mode == 1)
    {
      if (is_test_mode == 0)
      {
        if (verification_start_tick == 0)
        {
          verification_start_tick = HAL_GetTick();
          printf("[Verification] onstage_confirmed is 0. Settle timer started (500ms)...\r\n");
        }

        if (HAL_GetTick() - verification_start_tick < 500U)
        {
          // 刹车静止等待车体和传感器稳定
          Motor_Control(0, 0);
          osDelay(20);
          continue;
        }

        // 500ms 稳定时间已到，读取传感器确诊
        uint8_t low_grey_count = 0;
        if (Grey_Front < 180.0f) low_grey_count++;
        if (Grey_Back < 180.0f)  low_grey_count++;
        if (Grey_Left < 180.0f)  low_grey_count++;
        if (Grey_Right < 180.0f) low_grey_count++;

        uint8_t geometry_onstage = (IR_Distance_UP >= TOP_IR_THRESHOLD && IR_Distance_B >= 60.0f && (IR_Distance_L >= 50.0f || IR_Distance_R >= 50.0f));

        if (low_grey_count >= 3 || geometry_onstage)
        {
          onstage_confirmed = 1;
          verification_start_tick = 0; // 重置
          printf("[Verification] Confirmed ON-STAGE via %s! onstage_confirmed -> 1\r\n",
                 (low_grey_count >= 3) ? "Grey sensors" : "Geometry");
        }
        else
        {
          robot_state = ROBOT_TEST_ROTATE_PREPARE;
          verification_start_tick = 0; // 重置
          printf("[Verification] Failed to confirm on-stage. Transitioning to ROBOT_TEST_ROTATE_PREPARE to retry...\r\n");
          osDelay(20);
          continue;
        }
      }
    }

    if (control_mode == 0 && !Control_IsOnline() && !is_test_mode) {
        motor_target_speed[0] = 0.0f;
        motor_target_speed[1] = 0.0f;
        motor_target_speed[2] = 0.0f;
        motor_target_speed[3] = 0.0f;
        Motor_SetSpeed(MOTOR_1, 0);
        Motor_SetSpeed(MOTOR_2, 0);
        Motor_SetSpeed(MOTOR_3, 0);
        Motor_SetSpeed(MOTOR_4, 0);
    } else {
        PC_ControlData_t ctrl = Control_GetData();
        uint32_t prev_buttons = last_buttons;

        /* ========== 模式切换处理 ========== */
        /* button=48 使用上升沿切换遥控模式与自动控制模式 */
        if ((ctrl.buttons & 48) && !(prev_buttons & 48))
        {
          control_mode = !control_mode;  /* 切换模式 */
          printf("Mode switched: %s\r\n", control_mode ? "Auto Control" : "Remote Control");

          /* 切换模式时，关闭角度环控制 */
          if (control_mode == 1) {
            /* 进入自动控制模式，禁用角度环，并刷新(归零) IMU */
            IMU_ZeroZAxis();

            angle_control_enabled = 0;
            angle_control_prev = 0;
            /* 暂停角度环任务 */
            if (Angle_TaskHandle != NULL) {
              vTaskSuspend(Angle_TaskHandle);
            }
            /* 清空摇杆和角度速度 */
            motor_rc_speed[0] = 0.0f;
            motor_rc_speed[1] = 0.0f;
            motor_rc_speed[2] = 0.0f;
            motor_rc_speed[3] = 0.0f;
            motor_angle_speed[0] = 0.0f;
            motor_angle_speed[1] = 0.0f;
            motor_angle_speed[2] = 0.0f;
            motor_angle_speed[3] = 0.0f;
            target_angle = 0.0f;
          } else {
            /* 回到遥控模式，恢复 Angle_Task 准备随时启用 */
            if (Angle_TaskHandle != NULL) {
              vTaskResume(Angle_TaskHandle);
            }
          }
        }

        /* ========== 遥控模式 ========== */
        if (control_mode == 0)
        {
          verification_start_tick = 0; // 遥控模式下重置验证计时器
          /* 在遥控模式下，按下 gamepad Y 键 (buttons & 8) 立即进入自主登台流程（正式模式） */
          if ((ctrl.buttons & 8) && !(prev_buttons & 8))
          {
            is_test_mode = 0;
            robot_state = ROBOT_TEST_ROTATE_PREPARE;
            climb_pd_init = 0; /* 清空 PD 标志 */
            printf("[GamepadTrigger] Y received! Starting Auto Climb Scan...\r\n");
          }

          /* 始终通过统一入口写入基础摇杆指令，角度环会在 Angle_Task 中叠加修正 */
          Motor_Control((int16_t)ctrl.vy_lr, (int16_t)ctrl.vx_fwd);

          /* 舵机控制：固定速率转动
             - 只按lt：持续正向转动
             - 只按rt：持续反向转动
             - 松开：保持当前位置
             这样不会再因为输入�?�变化导致舵机频繁跳动 */
          if (ctrl.lt > 10 && ctrl.rt <= 10) {
            if (last_servo_angle + servo_step <= 180) {
              last_servo_angle += servo_step;
            } else {
              last_servo_angle = 180;
            }
            Servo_SetAngle(last_servo_angle);
          } else if (ctrl.rt > 10 && ctrl.lt <= 10) {
            if (last_servo_angle >= servo_step) {
              last_servo_angle -= servo_step;
            } else {
              last_servo_angle = 0;
            }
            Servo_SetAngle(last_servo_angle);
          }

          /* 在遥控模式下�???�??? button=4 的上升沿切换角度环模式 */
          if ((ctrl.buttons & (1U << 4)) && !(prev_buttons & (1U << 4)))
          {
            angle_control_enabled = !angle_control_enabled;
            printf("Angle Control: %s\r\n", angle_control_enabled ? "Enabled" : "Disabled");

            if (angle_control_enabled) {
              /* 启用角度环 */
              if (Angle_TaskHandle != NULL) {
                vTaskResume(Angle_TaskHandle);
              }
              target_angle = IMU_Data.Yaw;
              angle_control_prev = 0;
            } else {
              /* 禁用角度环，清除转向修正 */
              target_angle = 0.0f;
              PID_Clear(&Angle_pid[0]);
              motor_angle_speed[0] = 0.0f;
              motor_angle_speed[1] = 0.0f;
              motor_angle_speed[2] = 0.0f;
              motor_angle_speed[3] = 0.0f;
            }
          }
        }
        /* ========== 自动控制模式 ========== */
        else
        {
          if (onstage_confirmed == 1 || is_test_mode == 1)
          {
            if (is_vision_debug_mode > 0)
            {
              // 纯视觉调试模式下，为了在台架或桌面上调试时不被悬空的激光或高位灰度误判定为边缘风险导致卡死，
              // 我们传入虚拟的安全传感器数据（100mm 距离，100.0f 灰度），屏蔽调试期间的边缘触发。
              uint16_t dummy_laser1 = 100;
              uint16_t dummy_laser2 = 100;
              float dummy_grey_front = 100.0f;
              float dummy_grey_left = 100.0f;
              float dummy_grey_right = 100.0f;
              float dummy_grey_back = 100.0f;

              if (global_vision_target == 0 || global_vision_target == 1 || global_vision_target == 2)
              {
                Detect_Laser(&global_vision_target, &global_vision_yaw, &IR_Distance_F, &dummy_laser1, &dummy_laser2,
                             &dummy_grey_front, &dummy_grey_left, &dummy_grey_right, &dummy_grey_back);
              }
              else
              {
                Motor_Control(0, 0);
              }
            }
            else
            {
              // 正常自动控制逻辑
              // 新型传感器融合边缘检测（激光+前灰度）
              uint8_t edge_triggered = Motion_IsEdgeRisk(laser_dist_1, laser_dist_2, Grey_Front);
              Auto_Control_Logic_Laser(laser_dist_1, laser_dist_2, Grey_Front, Grey_Left, Grey_Right, Grey_Back);     //自动巡台

              if (edge_triggered)
              {
                  // 避障动作完成后，强制清零全局避障传感器缓存，防止采样率延迟导致二次误触发后退
                  laser_dist_1 = 0;
                  laser_dist_2 = 0;
                  osDelay(100); // 给传感器任务 100ms 采样刷新时间以更新真实值
              }
              else
              {
                  Detect_Laser(&global_vision_target, &global_vision_yaw, &IR_Distance_F, &laser_dist_1, &laser_dist_2,
                               &Grey_Front, &Grey_Left, &Grey_Right, &Grey_Back);  //自动检测能量块并推下
              }
            }
          }
          else
          {
            Motor_Control(0, 0);
          }
        }

        last_buttons = ctrl.buttons;
    }

    osDelay(20);
  }
  /* USER CODE END StartMotion_Task */
}

void StartAngle_Task(void *argument)
{
  /* USER CODE BEGIN StartAngle_Task */

  /* 初始化角度控制 PID（Yaw 偏航角控制）
     Kp=0.8, Ki=0.15, Kd=0.05：需根据实际机械动�?�调�???
     MaxOut=100：最大电机�?�度指令
     MaxIOut=50：最大积分输出
     DeadBand=2：接近目标时的死区（防止抖动）
     I_Separation=10：积分分离阈值 */
  PID_Init(&Angle_pid[0], 0.8f, 0.15f, 0.05f, 100.0f, 50.0f, 2.0f, 10.0f);

  /* Infinite loop */
  for(;;)
  {
    /* 检查状态变化：从禁用切换到启用 */
    if (angle_control_enabled && !angle_control_prev) {
      /* 刚启用，清除 PID 积分防止突跳，但保留上一周期的控制平稳性 */
      PID_Clear(&Angle_pid[0]);
    }
    angle_control_prev = angle_control_enabled;
        /* 清除上一周期的角度环转向修正 */
    for (int i = 0; i < 4; i++) {
      motor_angle_speed[i] = 0.0f;
    }
        /* 仅当角度环被启用时执行控制 */
    if (angle_control_enabled) {
      /* 从 IMU 读取当前偏航角作为反馈 */
      current_angle = IMU_Data.Yaw;

      /* PID 计算：计算达到目标偏航角�???�???的电机�?�度
         由于启用时 target_angle == current_angle，首个周期 PID 输出会接近 0
         这是正常的 - 用户手动启用时应该是静止状态�，然后再�?�过摇杆操作改变目标角度 */
      float angle_output = PID_Calc(&Angle_pid[0], target_angle, current_angle);

      /*
      motor_angle_speed[0] = angle_output;
      motor_angle_speed[1] = -angle_output;
      motor_angle_speed[2] = angle_output;
      motor_angle_speed[3] = -angle_output;
      */

      /* 打印调试信息 */
      //printf("Yaw Control: Target=%.2f°, Current=%.2f°, Output=%.1f\r\n", target_angle, current_angle, angle_output);

    }

    /* 50ms 周期与电机控制任务同步 */
    osDelay(50);
  }
  /* USER CODE END StartAngle_Task */
}

/* USER CODE BEGIN Application */
static void Debug_EnterOnstageRun(const char *source)
{
  is_test_mode = 1;
  control_mode = 1;
  onstage_confirmed = 1;
  verification_start_tick = 0;
  is_vision_debug_mode = 0; // Clear debug flag
  robot_state = ROBOT_RUNNING;
  Motor_Control(0, 0);
  printf("[SerialTrigger] %s received! Force ON-STAGE debug: ROBOT_RUNNING, auto mode, fall detection bypassed.\r\n",
         source);
}

void Trigger_Debug_Launch(void)
{
  Debug_EnterOnstageRun("Y");
}

void Trigger_Debug_RunOnstage(void)
{
  Debug_EnterOnstageRun("@RUN");
}

void Trigger_Debug_ClimbScan(void)
{
  is_test_mode = 1;
  control_mode = 1;
  onstage_confirmed = 0;
  verification_start_tick = 0;
  climb_pd_init = 0;
  is_vision_debug_mode = 0; // Clear debug flag
  climb_start_tick = HAL_GetTick();
  robot_state = ROBOT_TEST_ROTATE_PREPARE;
  Motor_Control(0, 0);
  printf("[SerialTrigger] @CLIMB received! Force climb/scan debug: ROBOT_TEST_ROTATE_PREPARE.\r\n");
}

void Trigger_Debug_Stop(void)
{
  is_test_mode = 0;
  control_mode = 0;
  onstage_confirmed = 0;
  verification_start_tick = 0;
  is_vision_debug_mode = 0; // Clear debug flag
  robot_state = ROBOT_FINISHED;
  Motor_Control(0, 0);
  printf("[SerialTrigger] @STOP received! Motors stopped. State -> ROBOT_FINISHED.\r\n");
}

void Trigger_Debug_VisionOnly(void)
{
  if (is_vision_debug_mode == 1)
  {
    // Toggle off: if already in SAFE debug mode, exit to STOP state
    Trigger_Debug_Stop();
  }
  else
  {
    is_vision_debug_mode = 1;
    is_test_mode = 1;
    control_mode = 1;
    onstage_confirmed = 1;
    verification_start_tick = 0;
    robot_state = ROBOT_RUNNING;
    Motor_Control(0, 0);
    printf("[SerialTrigger] @VISION received! Enter Vision-Only SAFE Debug Mode. Standby...\r\n");
  }
}

void Trigger_Debug_VisionActive(void)
{
  if (is_vision_debug_mode == 2)
  {
    // Toggle off: if already in ACTIVE debug mode, exit to STOP state
    Trigger_Debug_Stop();
  }
  else
  {
    is_vision_debug_mode = 2;
    is_test_mode = 1;
    control_mode = 1;
    onstage_confirmed = 1;
    verification_start_tick = 0;
    robot_state = ROBOT_RUNNING;
    Motor_Control(0, 0);
    printf("[SerialTrigger] @VISION_ACTIVE received! Enter Vision-Only ACTIVE Debug Mode. Standby...\r\n");
  }
}
/* USER CODE END Application */
